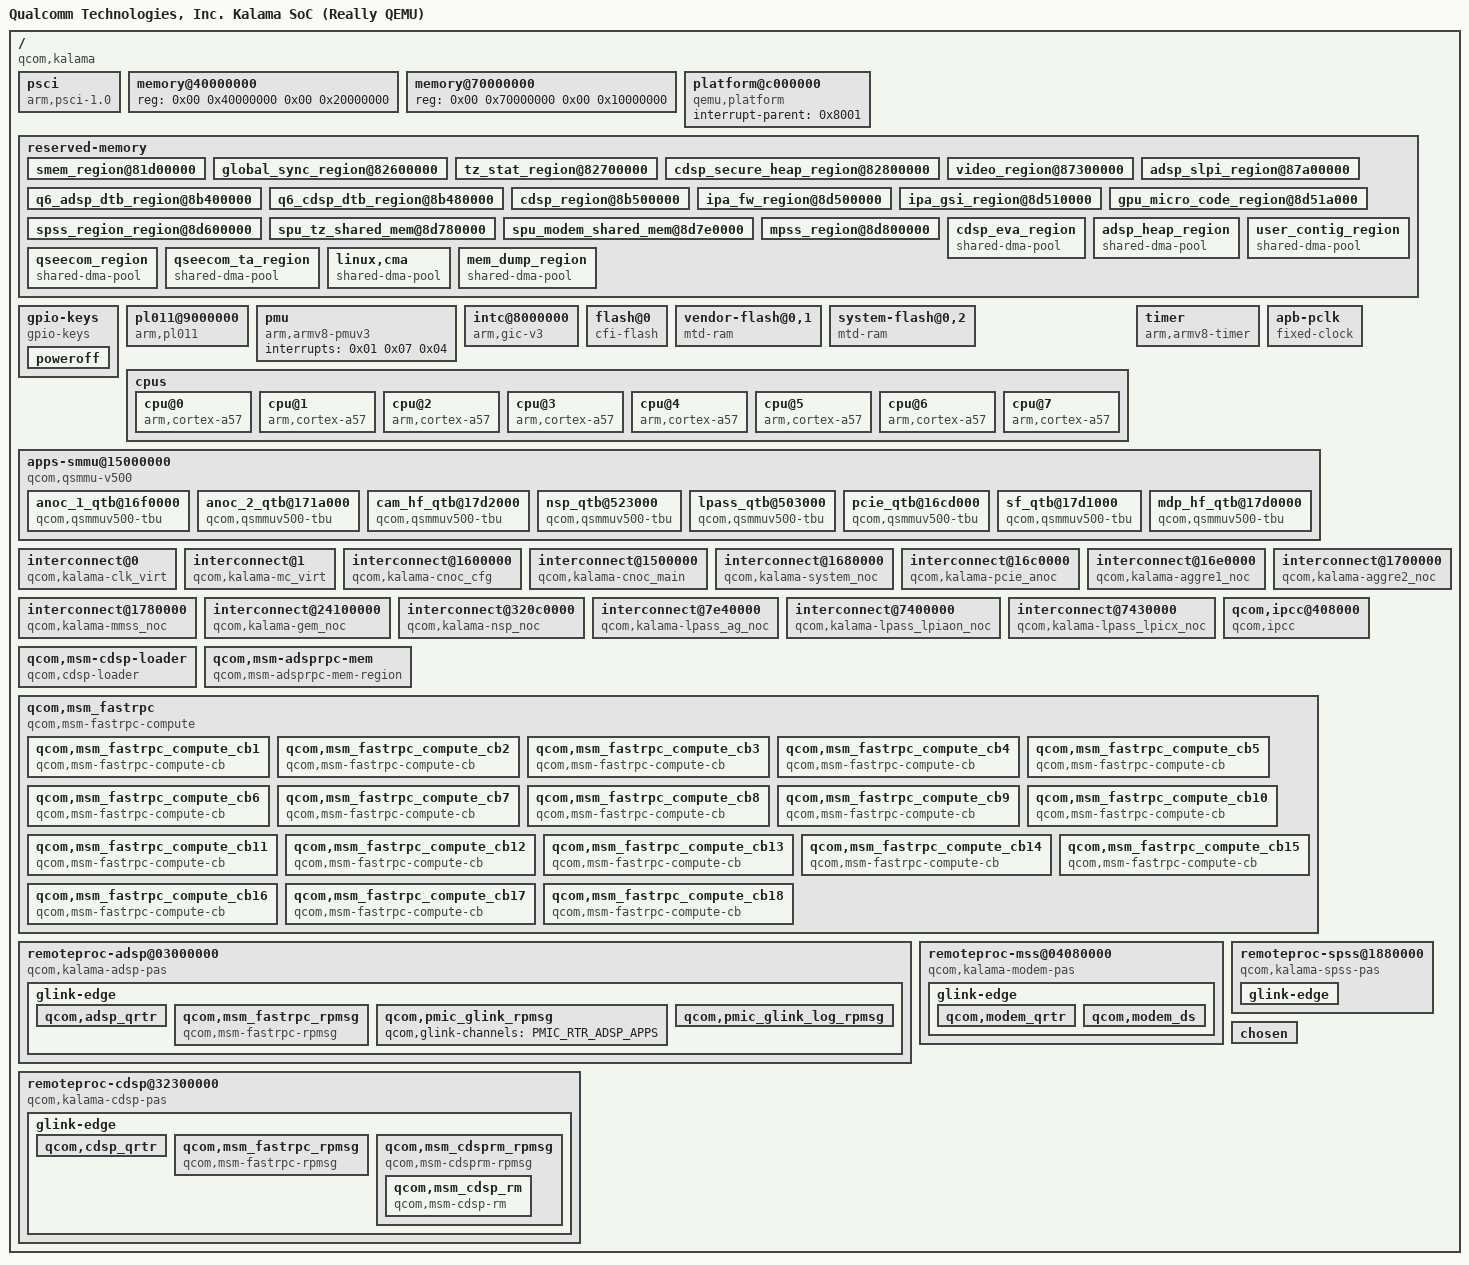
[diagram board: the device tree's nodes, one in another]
/dts-v1/;

/ {
	model = "Qualcomm Technologies, Inc. Kalama SoC (Really QEMU)";
	compatible = "qcom,kalama";
	qcom,msm-id = <0x207 0x10000>;
	interrupt-parent = <0x8001>;
	#size-cells = <0x02>;
	#address-cells = <0x02>;
	#compatible = "linux,dummy-virt";

	psci {
		migrate = <0xc4000005>;
		cpu_on = <0xc4000003>;
		cpu_off = <0x84000002>;
		cpu_suspend = <0xc4000001>;
		method = "smc";
		compatible = "arm,psci-1.0\0arm,psci";
	};

	memory@40000000 {
		reg = <0x00 0x40000000 0x00 0x20000000>;
		device_type = "memory";
	};

	memory@70000000 {
		reg = <0x00 0x70000000 0x00 0x10000000>;
		device_type = "memory";
	};

	platform@c000000 {
		interrupt-parent = <0x8001>;
		ranges = <0x00 0x00 0xc000000 0x2000000>;
		#address-cells = <0x01>;
		#size-cells = <0x01>;
		compatible = "qemu,platform\0simple-bus";
	};

	/*fw-cfg@9020000 {
		dma-coherent;
		reg = <0x00 0x9020000 0x00 0x18>;
		compatible = "qemu,fw-cfg-mmio";
	};
*/
	reserved-memory {
		#address-cells = <0x02>;
		#size-cells = <0x02>;
		ranges;
		phandle = <0x18d>;

		smem_region@81d00000 {
			no-map;
			reg = <0x00 0x81d00000 0x00 0x200000>;
			phandle = <0x50>;
		};

		global_sync_region@82600000 {
			no-map;
			reg = <0x00 0x82600000 0x00 0x100000>;
			phandle = <0x19b>;
		};

		tz_stat_region@82700000 {
			no-map;
			reg = <0x00 0x82700000 0x00 0x100000>;
			phandle = <0x19c>;
		};

		cdsp_secure_heap_region@82800000 {
			no-map;
			reg = <0x00 0x82800000 0x00 0x4600000>;
			phandle = <0x19d>;
		};

		video_region@87300000 {
			no-map;
			reg = <0x00 0x87300000 0x00 0x700000>;
			phandle = <0x19e>;
		};

		adsp_slpi_region@87a00000 {
			no-map;
			reg = <0x00 0x87a00000 0x00 0x3a00000>;
			phandle = <0x5e>;
		};

		q6_adsp_dtb_region@8b400000 {
			no-map;
			reg = <0x00 0x8b400000 0x00 0x80000>;
			phandle = <0x5f>;
		};

		q6_cdsp_dtb_region@8b480000 {
			no-map;
			reg = <0x00 0x8b480000 0x00 0x80000>;
			phandle = <0x64>;
		};

		cdsp_region@8b500000 {
			no-map;
			reg = <0x00 0x8b500000 0x00 0x2000000>;
			phandle = <0x63>;
		};

		ipa_fw_region@8d500000 {
			no-map;
			reg = <0x00 0x8d500000 0x00 0x10000>;
			phandle = <0x19f>;
		};

		ipa_gsi_region@8d510000 {
			no-map;
			reg = <0x00 0x8d510000 0x00 0xa000>;
			phandle = <0x1a0>;
		};

		gpu_micro_code_region@8d51a000 {
			no-map;
			reg = <0x00 0x8d51a000 0x00 0x2000>;
			phandle = <0x1a1>;
		};

		spss_region_region@8d600000 {
			no-map;
			reg = <0x00 0x8d600000 0x00 0x180000>;
			phandle = <0x6d>;
		};

		spu_tz_shared_mem@8d780000 {
			no-map;
			reg = <0x00 0x8d780000 0x00 0x60000>;
			phandle = <0x1a2>;
		};

		spu_modem_shared_mem@8d7e0000 {
			no-map;
			reg = <0x00 0x8d7e0000 0x00 0x20000>;
			phandle = <0x1a3>;
		};

		mpss_region@8d800000 {
			no-map;
			reg = <0x00 0x8d800000 0x00 0x13c00000>;
			phandle = <0x69>;
		};

		cdsp_eva_region {
			compatible = "shared-dma-pool";
			alloc-ranges = <0x00 0x00 0x00 0xffffffff>;
			reusable;
			alignment = <0x00 0x400000>;
			size = <0x00 0x400000>;
			phandle = <0x17d>;
		};

		adsp_heap_region {
			compatible = "shared-dma-pool";
			alloc-ranges = <0x00 0x00 0x00 0xffffffff>;
			reusable;
			alignment = <0x00 0x400000>;
			size = <0x00 0xc00000>;
			phandle = <0x58>;
		};

		user_contig_region {
			compatible = "shared-dma-pool";
			alloc-ranges = <0x00 0x00 0x00 0xffffffff>;
			reusable;
			alignment = <0x00 0x400000>;
			size = <0x00 0x1000000>;
			phandle = <0x31>;
		};

		qseecom_region {
			compatible = "shared-dma-pool";
			alloc-ranges = <0x00 0x00 0x00 0xffffffff>;
			reusable;
			alignment = <0x00 0x400000>;
			size = <0x00 0x1400000>;
			phandle = <0x2f>;
		};

		qseecom_ta_region {
			compatible = "shared-dma-pool";
			alloc-ranges = <0x00 0x00 0x00 0xffffffff>;
			reusable;
			alignment = <0x00 0x400000>;
			size = <0x00 0x1000000>;
			phandle = <0x30>;
		};

		linux,cma {
			compatible = "shared-dma-pool";
			alloc-ranges = <0x00 0x00 0x00 0xffffffff>;
			reusable;
			alignment = <0x00 0x400000>;
			size = <0x00 0x2000000>;
			linux,cma-default;
			phandle = <0x87>;
		};

		mem_dump_region {
			compatible = "shared-dma-pool";
			alloc-ranges = <0x01 0x00 0xfffffffe 0xffffffff>;
			reusable;
			alignment = <0x00 0x400000>;
			size = <0x00 0x3400000>;
			phandle = <0x173>;
		};
	};

	/*virtio_mmio@a000000 {
		dma-coherent;
		interrupts = <0x00 0x10 0x01>;
		reg = <0x00 0xa000000 0x00 0x200>;
		compatible = "virtio,mmio";
	};

	virtio_mmio@a000200 {
		dma-coherent;
		interrupts = <0x00 0x11 0x01>;
		reg = <0x00 0xa000200 0x00 0x200>;
		compatible = "virtio,mmio";
	};

	virtio_mmio@a000400 {
		dma-coherent;
		interrupts = <0x00 0x12 0x01>;
		reg = <0x00 0xa000400 0x00 0x200>;
		compatible = "virtio,mmio";
	};

	virtio_mmio@a000600 {
		dma-coherent;
		interrupts = <0x00 0x13 0x01>;
		reg = <0x00 0xa000600 0x00 0x200>;
		compatible = "virtio,mmio";
	};

	virtio_mmio@a000800 {
		dma-coherent;
		interrupts = <0x00 0x14 0x01>;
		reg = <0x00 0xa000800 0x00 0x200>;
		compatible = "virtio,mmio";
	};

	virtio_mmio@a000a00 {
		dma-coherent;
		interrupts = <0x00 0x15 0x01>;
		reg = <0x00 0xa000a00 0x00 0x200>;
		compatible = "virtio,mmio";
	};

	virtio_mmio@a000c00 {
		dma-coherent;
		interrupts = <0x00 0x16 0x01>;
		reg = <0x00 0xa000c00 0x00 0x200>;
		compatible = "virtio,mmio";
	};

	virtio_mmio@a000e00 {
		dma-coherent;
		interrupts = <0x00 0x17 0x01>;
		reg = <0x00 0xa000e00 0x00 0x200>;
		compatible = "virtio,mmio";
	};

	virtio_mmio@a001000 {
		dma-coherent;
		interrupts = <0x00 0x18 0x01>;
		reg = <0x00 0xa001000 0x00 0x200>;
		compatible = "virtio,mmio";
	};

	virtio_mmio@a001200 {
		dma-coherent;
		interrupts = <0x00 0x19 0x01>;
		reg = <0x00 0xa001200 0x00 0x200>;
		compatible = "virtio,mmio";
	};

	virtio_mmio@a001400 {
		dma-coherent;
		interrupts = <0x00 0x1a 0x01>;
		reg = <0x00 0xa001400 0x00 0x200>;
		compatible = "virtio,mmio";
	};

	virtio_mmio@a001600 {
		dma-coherent;
		interrupts = <0x00 0x1b 0x01>;
		reg = <0x00 0xa001600 0x00 0x200>;
		compatible = "virtio,mmio";
	};

	virtio_mmio@a001800 {
		dma-coherent;
		interrupts = <0x00 0x1c 0x01>;
		reg = <0x00 0xa001800 0x00 0x200>;
		compatible = "virtio,mmio";
	};

	virtio_mmio@a001a00 {
		dma-coherent;
		interrupts = <0x00 0x1d 0x01>;
		reg = <0x00 0xa001a00 0x00 0x200>;
		compatible = "virtio,mmio";
	};

	virtio_mmio@a001c00 {
		dma-coherent;
		interrupts = <0x00 0x1e 0x01>;
		reg = <0x00 0xa001c00 0x00 0x200>;
		compatible = "virtio,mmio";
	};

	virtio_mmio@a001e00 {
		dma-coherent;
		interrupts = <0x00 0x1f 0x01>;
		reg = <0x00 0xa001e00 0x00 0x200>;
		compatible = "virtio,mmio";
	};

	virtio_mmio@a002000 {
		dma-coherent;
		interrupts = <0x00 0x20 0x01>;
		reg = <0x00 0xa002000 0x00 0x200>;
		compatible = "virtio,mmio";
	};

	virtio_mmio@a002200 {
		dma-coherent;
		interrupts = <0x00 0x21 0x01>;
		reg = <0x00 0xa002200 0x00 0x200>;
		compatible = "virtio,mmio";
	};

	virtio_mmio@a002400 {
		dma-coherent;
		interrupts = <0x00 0x22 0x01>;
		reg = <0x00 0xa002400 0x00 0x200>;
		compatible = "virtio,mmio";
	};

	virtio_mmio@a002600 {
		dma-coherent;
		interrupts = <0x00 0x23 0x01>;
		reg = <0x00 0xa002600 0x00 0x200>;
		compatible = "virtio,mmio";
	};

	virtio_mmio@a002800 {
		dma-coherent;
		interrupts = <0x00 0x24 0x01>;
		reg = <0x00 0xa002800 0x00 0x200>;
		compatible = "virtio,mmio";
	};

	virtio_mmio@a002a00 {
		dma-coherent;
		interrupts = <0x00 0x25 0x01>;
		reg = <0x00 0xa002a00 0x00 0x200>;
		compatible = "virtio,mmio";
	};

	virtio_mmio@a002c00 {
		dma-coherent;
		interrupts = <0x00 0x26 0x01>;
		reg = <0x00 0xa002c00 0x00 0x200>;
		compatible = "virtio,mmio";
	};

	virtio_mmio@a002e00 {
		dma-coherent;
		interrupts = <0x00 0x27 0x01>;
		reg = <0x00 0xa002e00 0x00 0x200>;
		compatible = "virtio,mmio";
	};

	virtio_mmio@a003000 {
		dma-coherent;
		interrupts = <0x00 0x28 0x01>;
		reg = <0x00 0xa003000 0x00 0x200>;
		compatible = "virtio,mmio";
	};

	virtio_mmio@a003200 {
		dma-coherent;
		interrupts = <0x00 0x29 0x01>;
		reg = <0x00 0xa003200 0x00 0x200>;
		compatible = "virtio,mmio";
	};

	virtio_mmio@a003400 {
		dma-coherent;
		interrupts = <0x00 0x2a 0x01>;
		reg = <0x00 0xa003400 0x00 0x200>;
		compatible = "virtio,mmio";
	};

	virtio_mmio@a003600 {
		dma-coherent;
		interrupts = <0x00 0x2b 0x01>;
		reg = <0x00 0xa003600 0x00 0x200>;
		compatible = "virtio,mmio";
	};

	virtio_mmio@a003800 {
		dma-coherent;
		interrupts = <0x00 0x2c 0x01>;
		reg = <0x00 0xa003800 0x00 0x200>;
		compatible = "virtio,mmio";
	};

	virtio_mmio@a003a00 {
		dma-coherent;
		interrupts = <0x00 0x2d 0x01>;
		reg = <0x00 0xa003a00 0x00 0x200>;
		compatible = "virtio,mmio";
	};

	virtio_mmio@a003c00 {
		dma-coherent;
		interrupts = <0x00 0x2e 0x01>;
		reg = <0x00 0xa003c00 0x00 0x200>;
		compatible = "virtio,mmio";
	};

	virtio_mmio@a003e00 {
		dma-coherent;
		interrupts = <0x00 0x2f 0x01>;
		reg = <0x00 0xa003e00 0x00 0x200>;
		compatible = "virtio,mmio";
	};
*/
	gpio-keys {
		#address-cells = <0x01>;
		#size-cells = <0x00>;
		compatible = "gpio-keys";

		poweroff {
			gpios = <0x8002 0x03 0x00>;
			linux,code = <0x74>;
			label = "GPIO Key Poweroff";
		};
	};

	/*pl061@9030000 {
		phandle = <0x8002>;
		clock-names = "apb_pclk";
		clocks = <0x8000>;
		interrupts = <0x00 0x07 0x04>;
		gpio-controller;
		#gpio-cells = <0x02>;
		compatible = "arm,pl061\0arm,primecell";
		reg = <0x00 0x9030000 0x00 0x1000>;
	};*/

	/*pcie@10000000 {
		interrupt-map-mask = <0x1800 0x00 0x00 0x07>;
		interrupt-map = <0x00 0x00 0x00 0x01 0x8001 0x00 0x00 0x00 0x03 0x04 0x00 0x00 0x00 0x02 0x8001 0x00 0x00 0x00 0x04 0x04 0x00 0x00 0x00 0x03 0x8001 0x00 0x00 0x00 0x05 0x04 0x00 0x00 0x00 0x04 0x8001 0x00 0x00 0x00 0x06 0x04 0x800 0x00 0x00 0x01 0x8001 0x00 0x00 0x00 0x04 0x04 0x800 0x00 0x00 0x02 0x8001 0x00 0x00 0x00 0x05 0x04 0x800 0x00 0x00 0x03 0x8001 0x00 0x00 0x00 0x06 0x04 0x800 0x00 0x00 0x04 0x8001 0x00 0x00 0x00 0x03 0x04 0x1000 0x00 0x00 0x01 0x8001 0x00 0x00 0x00 0x05 0x04 0x1000 0x00 0x00 0x02 0x8001 0x00 0x00 0x00 0x06 0x04 0x1000 0x00 0x00 0x03 0x8001 0x00 0x00 0x00 0x03 0x04 0x1000 0x00 0x00 0x04 0x8001 0x00 0x00 0x00 0x04 0x04 0x1800 0x00 0x00 0x01 0x8001 0x00 0x00 0x00 0x06 0x04 0x1800 0x00 0x00 0x02 0x8001 0x00 0x00 0x00 0x03 0x04 0x1800 0x00 0x00 0x03 0x8001 0x00 0x00 0x00 0x04 0x04 0x1800 0x00 0x00 0x04 0x8001 0x00 0x00 0x00 0x05 0x04>;
		#interrupt-cells = <0x01>;
		ranges = <0x1000000 0x00 0x00 0x00 0x3eff0000 0x00 0x10000 0x2000000 0x00 0x10000000 0x00 0x10000000 0x00 0x2eff0000>;
		reg = <0x00 0x3f000000 0x00 0x1000000>;
		dma-coherent;
		bus-range = <0x00 0x0f>;
		linux,pci-domain = <0x00>;
		#size-cells = <0x02>;
		#address-cells = <0x03>;
		device_type = "pci";
		compatible = "pci-host-ecam-generic";
	};*/

	/*pl031@9010000 {
		clock-names = "apb_pclk";
		clocks = <0x8000>;
		interrupts = <0x00 0x02 0x04>;
		reg = <0x00 0x9010000 0x00 0x1000>;
		compatible = "arm,pl031\0arm,primecell";
	};*/

	pl011@9000000 {
		clock-names = "uartclk\0apb_pclk";
		clocks = <0x8000 0x8000>;
		interrupts = <0x00 0x01 0x04>;
		reg = <0x00 0x9000000 0x00 0x1000>;
		compatible = "arm,pl011\0arm,primecell";
	};

	pmu {
		interrupts = <0x01 0x07 0x04>;
		compatible = "arm,armv8-pmuv3";
	};

	intc@8000000 {
		phandle = <0x8001>;
		interrupts = <0x01 0x09 0x04>;
		reg = <0x00 0x8000000 0x00 0x10000 0x00 0x80a0000 0x00 0xf60000>;
		#redistributor-regions = <0x01>;
		compatible = "arm,gic-v3";
		ranges;
		#size-cells = <0x02>;
		#address-cells = <0x02>;
		interrupt-controller;
		#interrupt-cells = <0x03>;
	};

	flash@0 {
		bank-width = <0x04>;
		reg = <0x00 0x00 0x00 0x4000000 0x00 0x4000000 0x00 0x4000000>;
		compatible = "cfi-flash";
	};
	
	vendor-flash@0,1 {
		compatible = "mtd-ram";
		bank-width = <0x04>;
		reg = <0x00 0x10000000 0x00 0x20000000>;
	};
	system-flash@0,2 {
		compatible = "mtd-ram";
		bank-width = <0x04>;
		reg = <0x00 0x30000000 0x00 0x10000000>;
	};

	cpus {
		#size-cells = <0x00>;
		#address-cells = <0x01>;

		cpu@0 {
			reg = <0x00>;
			enable-method = "psci";
			compatible = "arm,cortex-a57";
			device_type = "cpu";
		};

		cpu@1 {
			reg = <0x01>;
			enable-method = "psci";
			compatible = "arm,cortex-a57";
			device_type = "cpu";
		};

		cpu@2 {
			reg = <0x02>;
			enable-method = "psci";
			compatible = "arm,cortex-a57";
			device_type = "cpu";
		};

		cpu@3 {
			reg = <0x03>;
			enable-method = "psci";
			compatible = "arm,cortex-a57";
			device_type = "cpu";
		};

		cpu@4 {
			reg = <0x04>;
			enable-method = "psci";
			compatible = "arm,cortex-a57";
			device_type = "cpu";
		};

		cpu@5 {
			reg = <0x05>;
			enable-method = "psci";
			compatible = "arm,cortex-a57";
			device_type = "cpu";
		};

		cpu@6 {
			reg = <0x06>;
			enable-method = "psci";
			compatible = "arm,cortex-a57";
			device_type = "cpu";
		};

		cpu@7 {
			reg = <0x07>;
			enable-method = "psci";
			compatible = "arm,cortex-a57";
			device_type = "cpu";
		};
	};

	timer {
		interrupts = <0x01 0x0d 0x04 0x01 0x0e 0x04 0x01 0x0b 0x04 0x01 0x0a 0x04>;
		always-on;
		compatible = "arm,armv8-timer\0arm,armv7-timer";
	};

	apb-pclk {
		phandle = <0x8000>;
		clock-output-names = "clk24mhz";
		clock-frequency = <0x16e3600>;
		#clock-cells = <0x00>;
		compatible = "fixed-clock";
	};

	apps-smmu@15000000 {
		compatible = "qcom,qsmmu-v500";
		reg = <0x15000000 0x100000>;
		#iommu-cells = <0x02>;
		qcom,use-3-lvl-tables;
		#global-interrupts = <0x01>;
		#size-cells = <0x01>;
		#address-cells = <0x01>;
		ranges;
		dma-coherent;
		interrupts = <0x00 0x41 0x04 0x00 0x61 0x04 0x00 0x62 0x04 0x00 0x63 0x04 0x00 0x64 0x04 0x00 0x65 0x04 0x00 0x66 0x04 0x00 0x67 0x04 0x00 0x68 0x04 0x00 0x69 0x04 0x00 0x6a 0x04 0x00 0x6b 0x04 0x00 0x6c 0x04 0x00 0x6d 0x04 0x00 0x6e 0x04 0x00 0x6f 0x04 0x00 0x70 0x04 0x00 0x71 0x04 0x00 0x72 0x04 0x00 0x73 0x04 0x00 0x74 0x04 0x00 0x75 0x04 0x00 0x76 0x04 0x00 0xb5 0x04 0x00 0xb6 0x04 0x00 0xb7 0x04 0x00 0xb8 0x04 0x00 0xb9 0x04 0x00 0xba 0x04 0x00 0xbb 0x04 0x00 0xbc 0x04 0x00 0xbd 0x04 0x00 0xbe 0x04 0x00 0xbf 0x04 0x00 0xc0 0x04 0x00 0x13b 0x04 0x00 0x13c 0x04 0x00 0x13d 0x04 0x00 0x13e 0x04 0x00 0x13f 0x04 0x00 0x140 0x04 0x00 0x141 0x04 0x00 0x142 0x04 0x00 0x143 0x04 0x00 0x144 0x04 0x00 0x145 0x04 0x00 0x146 0x04 0x00 0x147 0x04 0x00 0x148 0x04 0x00 0x149 0x04 0x00 0x14a 0x04 0x00 0x14b 0x04 0x00 0x14c 0x04 0x00 0x14d 0x04 0x00 0x14e 0x04 0x00 0x14f 0x04 0x00 0x150 0x04 0x00 0x151 0x04 0x00 0x152 0x04 0x00 0x153 0x04 0x00 0x154 0x04 0x00 0x155 0x04 0x00 0x156 0x04 0x00 0x157 0x04 0x00 0x158 0x04 0x00 0x159 0x04 0x00 0x18b 0x04 0x00 0x18c 0x04 0x00 0x18d 0x04 0x00 0x18e 0x04 0x00 0x18f 0x04 0x00 0x190 0x04 0x00 0x191 0x04 0x00 0x192 0x04 0x00 0x193 0x04 0x00 0x194 0x04 0x00 0x195 0x04 0x00 0x196 0x04 0x00 0x197 0x04 0x00 0x198 0x04 0x00 0x199 0x04 0x00 0x1a2 0x04 0x00 0x1a3 0x04 0x00 0x19c 0x04 0x00 0x1a5 0x04 0x00 0x2c2 0x04 0x00 0x1a7 0x04 0x00 0x1a8 0x04 0x00 0x1a9 0x04 0x00 0x2b1 0x04 0x00 0x2b2 0x04 0x00 0x2b3 0x04 0x00 0x2b4 0x04 0x00 0x2b5 0x04 0x00 0x2b6 0x04 0x00 0x2b7 0x04 0x00 0x2b8 0x04>;
		qcom,actlr = <0x18a0 0x40 0x103 0x800 0x20 0x01 0x1800 0xc0 0x01 0x1820 0x00 0x01 0x1860 0x00 0x01 0xc01 0x20 0x303 0xc02 0x20 0x303 0xc03 0x20 0x303 0xc04 0x20 0x303 0xc05 0x20 0x303 0xc06 0x20 0x303 0xc07 0x20 0x303 0xc08 0x20 0x303 0xc09 0x20 0x303 0xc0b 0x20 0x303 0xc0c 0x20 0x303 0xc0d 0x20 0x303 0xc0e 0x20 0x303 0xc0f 0x20 0x303 0x1961 0x00 0x303 0x1962 0x00 0x303 0x1963 0x00 0x303 0x1964 0x00 0x303 0x1965 0x00 0x303 0x1966 0x00 0x303 0x1967 0x00 0x303 0x1968 0x00 0x303 0x1969 0x00 0x303 0x196b 0x00 0x303 0x196c 0x00 0x303 0x196d 0x00 0x303 0x196e 0x00 0x303 0x196f 0x00 0x303 0x19c1 0x00 0x303 0x19c2 0x00 0x303 0x19c3 0x00 0x303 0x19c4 0x00 0x303 0x19c5 0x00 0x303 0x19c6 0x00 0x303 0x19c7 0x00 0x303 0x19c8 0x00 0x303 0x19c9 0x00 0x303 0x19cb 0x00 0x303 0x19cc 0x00 0x303 0x19cd 0x00 0x303 0x19ce 0x00 0x303 0x19cf 0x00 0x303 0x1c00 0x02 0x01 0x1c01 0x00 0x01 0x1920 0x00 0x103 0x1923 0x00 0x103 0x1924 0x00 0x103 0x1940 0x00 0x103 0x1941 0x04 0x103 0x1943 0x00 0x103 0x1944 0x00 0x103 0x1947 0x00 0x103>;
		phandle = <0x4c>;

		anoc_1_qtb@16f0000 {
			compatible = "qcom,qsmmuv500-tbu\0qcom,qtb500";
			reg = <0x16f0000 0x1000>;
			qcom,stream-id-range = <0x00 0x400>;
			qcom,iova-width = <0x24>;
			interconnects = <0x84 0x09 0x5c 0x200>;
			qcom,num-qtb-ports = <0x01>;
			phandle = <0x232>;
		};

		anoc_2_qtb@171a000 {
			compatible = "qcom,qsmmuv500-tbu\0qcom,qtb500";
			reg = <0x171a000 0x1000>;
			qcom,stream-id-range = <0x400 0x400>;
			qcom,iova-width = <0x24>;
			interconnects = <0x84 0x0a 0x5c 0x200>;
			qcom,num-qtb-ports = <0x01>;
			phandle = <0x233>;
		};

		cam_hf_qtb@17d2000 {
			compatible = "qcom,qsmmuv500-tbu\0qcom,qtb500";
			reg = <0x17d2000 0x1000>;
			qcom,stream-id-range = <0x800 0x400>;
			qcom,iova-width = <0x24>;
			interconnects = <0x85 0x0b 0x5c 0x200>;
			qcom,num-qtb-ports = <0x02>;
			phandle = <0x234>;
		};

		nsp_qtb@523000 {
			compatible = "qcom,qsmmuv500-tbu\0qcom,qtb500";
			reg = <0x523000 0x1000>;
			qcom,stream-id-range = <0xc00 0x400>;
			qcom,iova-width = <0x22>;
			interconnects = <0x65 0x2a 0x5c 0x200>;
			qcom,num-qtb-ports = <0x02>;
			phandle = <0x235>;
		};

		lpass_qtb@503000 {
			compatible = "qcom,qsmmuv500-tbu\0qcom,qtb500";
			reg = <0x503000 0x1000>;
			qcom,stream-id-range = <0x1000 0x400>;
			qcom,iova-width = <0x20>;
			interconnects = <0x5b 0x29 0x5c 0x200>;
			qcom,num-qtb-ports = <0x01>;
			phandle = <0x236>;
		};

		pcie_qtb@16cd000 {
			compatible = "qcom,qsmmuv500-tbu\0qcom,qtb500";
			reg = <0x16cd000 0x1000>;
			qcom,stream-id-range = <0x1400 0x400>;
			qcom,iova-width = <0x24>;
			interconnects = <0x86 0x2d 0x5c 0x200>;
			qcom,num-qtb-ports = <0x01>;
			phandle = <0x237>;
		};

		sf_qtb@17d1000 {
			compatible = "qcom,qsmmuv500-tbu\0qcom,qtb500";
			reg = <0x17d1000 0x1000>;
			qcom,stream-id-range = <0x1800 0x400>;
			qcom,iova-width = <0x24>;
			interconnects = <0x85 0x1d 0x5c 0x200>;
			qcom,num-qtb-ports = <0x02>;
			phandle = <0x238>;
		};

		mdp_hf_qtb@17d0000 {
			compatible = "qcom,qsmmuv500-tbu\0qcom,qtb500";
			reg = <0x17d0000 0x1000>;
			qcom,stream-id-range = <0x1c00 0x400>;
			qcom,iova-width = <0x20>;
			interconnects = <0x85 0x14 0x5c 0x200>;
			qcom,num-qtb-ports = <0x02>;
			phandle = <0x239>;
		};
	};

	interconnect@0 {
		compatible = "qcom,kalama-clk_virt";
		#interconnect-cells = <0x01>;
		qcom,bcm-voter-names = "hlos";
		qcom,bcm-voters = <0x2b>;
		phandle = <0x1c9>;
	};

	interconnect@1 {
		compatible = "qcom,kalama-mc_virt";
		#interconnect-cells = <0x01>;
		qcom,bcm-voter-names = "hlos\0disp";
		qcom,bcm-voters = <0x2b 0x2c>;
		phandle = <0x5c>;
	};

	interconnect@1600000 {
		compatible = "qcom,kalama-cnoc_cfg";
		reg = <0x1600000 0x6200>;
		#interconnect-cells = <0x01>;
		qcom,bcm-voter-names = "hlos";
		qcom,bcm-voters = <0x2b>;
		phandle = <0x177>;
	};

	interconnect@1500000 {
		compatible = "qcom,kalama-cnoc_main";
		reg = <0x1500000 0x13080>;
		#interconnect-cells = <0x01>;
		qcom,bcm-voter-names = "hlos";
		qcom,bcm-voters = <0x2b>;
		phandle = <0x1ca>;
	};

	interconnect@1680000 {
		compatible = "qcom,kalama-system_noc";
		reg = <0x1680000 0x1d080>;
		#interconnect-cells = <0x01>;
		qcom,bcm-voter-names = "hlos";
		qcom,bcm-voters = <0x2b>;
		phandle = <0x84>;
	};

	interconnect@16c0000 {
		compatible = "qcom,kalama-pcie_anoc";
		reg = <0x16c0000 0x12200>;
		#interconnect-cells = <0x01>;
		clocks = <0x2d 0x00 0x2d 0x0a>;
		qcom,bcm-voter-names = "hlos";
		qcom,bcm-voters = <0x2b>;
		qcom,skip-qos;
		phandle = <0x86>;
	};

	interconnect@16e0000 {
		compatible = "qcom,kalama-aggre1_noc";
		reg = <0x16e0000 0x14400>;
		#interconnect-cells = <0x01>;
		clocks = <0x2d 0x01 0x2d 0x03>;
		qcom,bcm-voter-names = "hlos";
		qcom,bcm-voters = <0x2b>;
		qcom,skip-qos;
		phandle = <0x176>;
	};

	interconnect@1700000 {
		compatible = "qcom,kalama-aggre2_noc";
		reg = <0x1700000 0x1e400>;
		#interconnect-cells = <0x01>;
		qcom,bcm-voter-names = "hlos";
		qcom,bcm-voters = <0x2b>;
		clocks = <0x2e 0x0c>;
		qcom,skip-qos;
		phandle = <0x5d>;
	};

	interconnect@1780000 {
		compatible = "qcom,kalama-mmss_noc";
		reg = <0x1780000 0x5b800>;
		#interconnect-cells = <0x01>;
		qcom,bcm-voter-names = "hlos\0disp";
		qcom,bcm-voters = <0x2b 0x2c>;
		qcom,skip-qos;
		phandle = <0x85>;
	};

	interconnect@24100000 {
		compatible = "qcom,kalama-gem_noc";
		reg = <0x24100000 0xbb800>;
		#interconnect-cells = <0x01>;
		qcom,bcm-voter-names = "hlos\0disp";
		qcom,bcm-voters = <0x2b 0x2c>;
		qcom,skip-qos;
		phandle = <0x76>;
	};

	interconnect@320c0000 {
		compatible = "qcom,kalama-nsp_noc";
		reg = <0x320c0000 0xe080>;
		#interconnect-cells = <0x01>;
		qcom,bcm-voter-names = "hlos";
		qcom,bcm-voters = <0x2b>;
		phandle = <0x65>;
	};

	interconnect@7e40000 {
		compatible = "qcom,kalama-lpass_ag_noc";
		reg = <0x7e40000 0xe080>;
		#interconnect-cells = <0x01>;
		qcom,bcm-voter-names = "hlos";
		qcom,bcm-voters = <0x2b>;
		phandle = <0x1cb>;
	};

	interconnect@7400000 {
		compatible = "qcom,kalama-lpass_lpiaon_noc";
		reg = <0x7400000 0x19080>;
		#interconnect-cells = <0x01>;
		qcom,bcm-voter-names = "hlos";
		qcom,bcm-voters = <0x2b>;
		phandle = <0x1cc>;
	};

	interconnect@7430000 {
		compatible = "qcom,kalama-lpass_lpicx_noc";
		reg = <0x7430000 0x3a200>;
		#interconnect-cells = <0x01>;
		qcom,bcm-voter-names = "hlos";
		qcom,bcm-voters = <0x2b>;
		phandle = <0x5b>;
	};

	qcom,ipcc@408000 {
		compatible = "qcom,ipcc";
		reg = <0x408000 0x1000>;
		interrupts = <0x00 0xe5 0x04>;
		interrupt-controller;
		#interrupt-cells = <0x03>;
		#mbox-cells = <0x02>;
		phandle = <0x52>;
	};

	qcom,msm-cdsp-loader {
		compatible = "qcom,cdsp-loader";
		qcom,proc-img-to-load = "cdsp";
		qcom,rproc-handle = <0x57>;
	};

	qcom,msm-adsprpc-mem {
		compatible = "qcom,msm-adsprpc-mem-region";
		memory-region = <0x58>;
		restrict-access;
	};

	qcom,msm_fastrpc {
		compatible = "qcom,msm-fastrpc-compute";
		qcom,adsp-remoteheap-vmid = <0x16 0x25>;
		qcom,fastrpc-adsp-audio-pdr;
		qcom,fastrpc-adsp-sensors-pdr;
		qcom,rpc-latency-us = <0xeb>;
		qcom,fastrpc-gids = <0xb5c>;
		qcom,qos-cores = <0x00 0x01 0x02 0x03>;
		phandle = <0x21b>;

		qcom,msm_fastrpc_compute_cb1 {
			compatible = "qcom,msm-fastrpc-compute-cb";
			label = "cdsprpc-smd";
			iommus = <0x4c 0x1961 0x00 0x4c 0xc01 0x20 0x4c 0x19c1 0x10>;
			qcom,iommu-dma-addr-pool = <0x80000000 0x78000000>;
			qcom,iommu-faults = "stall-disable\0HUPCF";
			dma-coherent;
		};

		qcom,msm_fastrpc_compute_cb2 {
			compatible = "qcom,msm-fastrpc-compute-cb";
			label = "cdsprpc-smd";
			iommus = <0x4c 0x1962 0x00 0x4c 0xc02 0x20 0x4c 0x19c2 0x10>;
			qcom,iommu-dma-addr-pool = <0x80000000 0x78000000>;
			qcom,iommu-faults = "stall-disable\0HUPCF";
			dma-coherent;
		};

		qcom,msm_fastrpc_compute_cb3 {
			compatible = "qcom,msm-fastrpc-compute-cb";
			label = "cdsprpc-smd";
			iommus = <0x4c 0x1963 0x00 0x4c 0xc03 0x20 0x4c 0x19c3 0x10>;
			qcom,iommu-dma-addr-pool = <0x80000000 0x78000000>;
			qcom,iommu-faults = "stall-disable\0HUPCF";
			dma-coherent;
		};

		qcom,msm_fastrpc_compute_cb4 {
			compatible = "qcom,msm-fastrpc-compute-cb";
			label = "cdsprpc-smd";
			iommus = <0x4c 0x1964 0x00 0x4c 0xc04 0x20 0x4c 0x19c4 0x10>;
			qcom,iommu-dma-addr-pool = <0x80000000 0x78000000>;
			qcom,iommu-faults = "stall-disable\0HUPCF";
			dma-coherent;
		};

		qcom,msm_fastrpc_compute_cb5 {
			compatible = "qcom,msm-fastrpc-compute-cb";
			label = "cdsprpc-smd";
			iommus = <0x4c 0x1965 0x00 0x4c 0xc05 0x20 0x4c 0x19c5 0x10>;
			qcom,iommu-dma-addr-pool = <0x80000000 0x78000000>;
			qcom,iommu-faults = "stall-disable\0HUPCF";
			dma-coherent;
		};

		qcom,msm_fastrpc_compute_cb6 {
			compatible = "qcom,msm-fastrpc-compute-cb";
			label = "cdsprpc-smd";
			iommus = <0x4c 0x1966 0x00 0x4c 0xc06 0x20 0x4c 0x19c6 0x10>;
			qcom,iommu-dma-addr-pool = <0x80000000 0x78000000>;
			qcom,iommu-faults = "stall-disable\0HUPCF";
			dma-coherent;
		};

		qcom,msm_fastrpc_compute_cb7 {
			compatible = "qcom,msm-fastrpc-compute-cb";
			label = "cdsprpc-smd";
			iommus = <0x4c 0x1967 0x00 0x4c 0xc07 0x20 0x4c 0x19c7 0x10>;
			qcom,iommu-dma-addr-pool = <0x80000000 0x78000000>;
			qcom,iommu-faults = "stall-disable\0HUPCF";
			dma-coherent;
		};

		qcom,msm_fastrpc_compute_cb8 {
			compatible = "qcom,msm-fastrpc-compute-cb";
			label = "cdsprpc-smd";
			iommus = <0x4c 0x1968 0x00 0x4c 0xc08 0x20 0x4c 0x19c8 0x10>;
			qcom,iommu-dma-addr-pool = <0x80000000 0x78000000>;
			qcom,iommu-faults = "stall-disable\0HUPCF";
			dma-coherent;
		};

		qcom,msm_fastrpc_compute_cb9 {
			compatible = "qcom,msm-fastrpc-compute-cb";
			label = "cdsprpc-smd";
			qcom,secure-context-bank;
			iommus = <0x4c 0x1969 0x00 0x4c 0xc09 0x20 0x4c 0x19c9 0x10>;
			qcom,iommu-dma-addr-pool = <0x60000000 0x78000000>;
			qcom,iommu-faults = "stall-disable\0HUPCF";
			qcom,iommu-vmid = <0x0a>;
			dma-coherent;
		};

		qcom,msm_fastrpc_compute_cb10 {
			compatible = "qcom,msm-fastrpc-compute-cb";
			label = "adsprpc-smd";
			iommus = <0x4c 0x1003 0x80 0x4c 0x1063 0x00>;
			qcom,iommu-dma-addr-pool = <0x80000000 0x78000000>;
			qcom,iommu-faults = "stall-disable\0HUPCF";
			dma-coherent;
		};

		qcom,msm_fastrpc_compute_cb11 {
			compatible = "qcom,msm-fastrpc-compute-cb";
			label = "adsprpc-smd";
			iommus = <0x4c 0x1004 0x80 0x4c 0x1064 0x00>;
			qcom,iommu-dma-addr-pool = <0x80000000 0x78000000>;
			qcom,iommu-faults = "stall-disable\0HUPCF";
			dma-coherent;
		};

		qcom,msm_fastrpc_compute_cb12 {
			compatible = "qcom,msm-fastrpc-compute-cb";
			label = "adsprpc-smd";
			iommus = <0x4c 0x1005 0x80 0x4c 0x1065 0x00>;
			qcom,iommu-dma-addr-pool = <0x80000000 0x78000000>;
			qcom,iommu-faults = "stall-disable\0HUPCF";
			dma-coherent;
		};

		qcom,msm_fastrpc_compute_cb13 {
			compatible = "qcom,msm-fastrpc-compute-cb";
			label = "adsprpc-smd";
			iommus = <0x4c 0x1006 0x80 0x4c 0x1066 0x00>;
			qcom,iommu-dma-addr-pool = <0x80000000 0x78000000>;
			qcom,iommu-faults = "stall-disable\0HUPCF";
			dma-coherent;
		};

		qcom,msm_fastrpc_compute_cb14 {
			compatible = "qcom,msm-fastrpc-compute-cb";
			label = "adsprpc-smd";
			iommus = <0x4c 0x1007 0x80 0x4c 0x1067 0x00>;
			qcom,iommu-dma-addr-pool = <0x80000000 0x78000000>;
			qcom,iommu-faults = "stall-disable\0HUPCF";
			dma-coherent;
		};

		qcom,msm_fastrpc_compute_cb15 {
			compatible = "qcom,msm-fastrpc-compute-cb";
			label = "cdsprpc-smd";
			iommus = <0x4c 0x196c 0x00 0x4c 0xc0c 0x20 0x4c 0x19cc 0x10>;
			qcom,iommu-dma-addr-pool = <0x80000000 0x78000000>;
			qcom,iommu-faults = "stall-disable\0HUPCF";
			dma-coherent;
		};

		qcom,msm_fastrpc_compute_cb16 {
			compatible = "qcom,msm-fastrpc-compute-cb";
			label = "cdsprpc-smd";
			iommus = <0x4c 0x196d 0x00 0x4c 0xc0d 0x20 0x4c 0x19cd 0x10>;
			qcom,iommu-dma-addr-pool = <0x80000000 0x78000000>;
			qcom,iommu-faults = "stall-disable\0HUPCF";
			dma-coherent;
		};

		qcom,msm_fastrpc_compute_cb17 {
			compatible = "qcom,msm-fastrpc-compute-cb";
			label = "cdsprpc-smd";
			iommus = <0x4c 0x196e 0x00 0x4c 0xc0e 0x20 0x4c 0x19ce 0x10>;
			qcom,iommu-dma-addr-pool = <0x80000000 0x78000000>;
			qcom,iommu-faults = "stall-disable\0HUPCF";
			dma-coherent;
		};

		qcom,msm_fastrpc_compute_cb18 {
			compatible = "qcom,msm-fastrpc-compute-cb";
			label = "cdsprpc-smd";
			iommus = <0x4c 0x196f 0x00 0x4c 0xc0f 0x20 0x4c 0x19cf 0x10>;
			qcom,iommu-dma-addr-pool = <0x80000000 0x78000000>;
			qcom,iommu-faults = "stall-disable\0HUPCF";
			dma-coherent;
		};
	};

	remoteproc-adsp@03000000 {
		compatible = "qcom,kalama-adsp-pas";
		reg = <0x3000000 0x10000>;
		status = "ok";
		cx-supply = <0x59>;
		cx-uV-uA = <0x180 0x00>;
		mx-supply = <0x5a>;
		mx-uV-uA = <0x180 0x00>;
		reg-names = "cx\0mx";
		clocks = <0x2e 0x00>;
		clock-names = "xo";
		qcom,qmp = <0x53>;
		interconnects = <0x5b 0x29 0x5c 0x200 0x5d 0x27 0x5c 0x200>;
		interconnect-names = "rproc_ddr\0crypto_ddr";
		memory-region = <0x5e 0x5f>;
		interrupts-extended = <0x32 0x06 0x01 0x60 0x00 0x00 0x60 0x02 0x00 0x60 0x01 0x00 0x60 0x03 0x00>;
		interrupt-names = "wdog\0fatal\0handover\0ready\0stop-ack";
		qcom,smem-states = <0x61 0x00>;
		qcom,smem-state-names = "stop";
		phandle = <0x21c>;

		glink-edge {
			qcom,remote-pid = <0x02>;
			transport = "smem";
			mboxes = <0x52 0x03 0x00>;
			mbox-names = "adsp_smem";
			interrupt-parent = <0x52>;
			interrupts = <0x03 0x00 0x01>;
			label = "adsp";
			qcom,glink-label = "lpass";
			phandle = <0x21d>;

			qcom,adsp_qrtr {
				qcom,glink-channels = "IPCRTR";
				qcom,intents = <0x800 0x05 0x2000 0x03 0x4400 0x02>;
			};

			qcom,msm_fastrpc_rpmsg {
				compatible = "qcom,msm-fastrpc-rpmsg";
				qcom,glink-channels = "fastrpcglink-apps-dsp";
				qcom,intents = <0x64 0x40>;
			};

			qcom,pmic_glink_rpmsg {
				qcom,glink-channels = "PMIC_RTR_ADSP_APPS";
			};

			qcom,pmic_glink_log_rpmsg {
				qcom,glink-channels = "PMIC_LOGS_ADSP_APPS";
				qcom,intents = <0x800 0x05 0xc00 0x03 0x2000 0x01>;
			};
		};
	};

	remoteproc-cdsp@32300000 {
		compatible = "qcom,kalama-cdsp-pas";
		reg = <0x32300000 0x10000>;
		status = "ok";
		cx-supply = <0x21>;
		cx-uV-uA = <0x180 0x186a0>;
		mx-supply = <0x25>;
		mx-uV-uA = <0x180 0x186a0>;
		nsp-supply = <0x62>;
		nsp-uV-uA = <0x180 0x186a0>;
		reg-names = "cx\0mx\0nsp";
		memory-region = <0x63 0x64>;
		clocks = <0x2e 0x00>;
		clock-names = "xo";
		qcom,qmp = <0x53>;
		interconnects = <0x65 0x2a 0x5c 0x200 0x5d 0x27 0x5c 0x200>;
		interconnect-names = "rproc_ddr\0crypto_ddr";
		interrupts-extended = <0x01 0x00 0x242 0x01 0x66 0x00 0x00 0x66 0x02 0x00 0x66 0x01 0x00 0x66 0x03 0x00>;
		interrupt-names = "wdog\0fatal\0handover\0ready\0stop-ack";
		qcom,smem-states = <0x67 0x00>;
		qcom,smem-state-names = "stop";
		phandle = <0x57>;

		glink-edge {
			qcom,remote-pid = <0x05>;
			transport = "smem";
			mboxes = <0x52 0x06 0x00>;
			mbox-names = "cdsp_smem";
			interrupt-parent = <0x52>;
			interrupts = <0x06 0x00 0x01>;
			label = "cdsp";
			qcom,glink-label = "cdsp";

			qcom,cdsp_qrtr {
				qcom,glink-channels = "IPCRTR";
				qcom,intents = <0x800 0x05 0x2000 0x03 0x4400 0x02>;
			};

			qcom,msm_fastrpc_rpmsg {
				compatible = "qcom,msm-fastrpc-rpmsg";
				qcom,glink-channels = "fastrpcglink-apps-dsp";
				qcom,intents = <0x64 0x40>;
			};

			qcom,msm_cdsprm_rpmsg {
				compatible = "qcom,msm-cdsprm-rpmsg";
				qcom,glink-channels = "cdsprmglink-apps-dsp";
				qcom,intents = <0x20 0x0c>;

				qcom,msm_cdsp_rm {
					compatible = "qcom,msm-cdsp-rm";
					qcom,qos-latency-us = <0x46>;
					qcom,qos-maxhold-ms = <0x14>;
					phandle = <0x21e>;
				};
			};
		};
	};

	remoteproc-mss@04080000 {
		compatible = "qcom,kalama-modem-pas";
		reg = <0x4080000 0x10000>;
		status = "ok";
		clocks = <0x2e 0x00>;
		clock-names = "xo";
		cx-supply = <0x21>;
		cx-uV-uA = <0x180 0x186a0>;
		mx-supply = <0x68>;
		mx-uV-uA = <0x180 0x186a0>;
		reg-names = "cx\0mx";
		qcom,qmp = <0x53>;
		interconnects = <0x5d 0x27 0x5c 0x200>;
		interconnect-names = "crypto_ddr";
		memory-region = <0x69 0x6a>;
		interrupts-extended = <0x01 0x00 0x108 0x01 0x6b 0x00 0x00 0x6b 0x02 0x00 0x6b 0x01 0x00 0x6b 0x03 0x00 0x6b 0x07 0x00>;
		interrupt-names = "wdog\0fatal\0handover\0ready\0stop-ack\0shutdown-ack";
		qcom,smem-states = <0x6c 0x00>;
		qcom,smem-state-names = "stop";
		phandle = <0x21f>;

		glink-edge {
			qcom,remote-pid = <0x01>;
			transport = "smem";
			mboxes = <0x52 0x02 0x00>;
			mbox-names = "mpss_smem";
			interrupt-parent = <0x52>;
			interrupts = <0x02 0x00 0x01>;
			label = "modem";
			qcom,glink-label = "mpss";

			qcom,modem_qrtr {
				qcom,glink-channels = "IPCRTR";
				qcom,low-latency;
				qcom,intents = <0x800 0x05 0x2000 0x03 0x4400 0x02>;
			};

			qcom,modem_ds {
				qcom,glink-channels = "DS";
				qcom,intents = <0x4000 0x02>;
			};
		};
	};

	remoteproc-spss@1880000 {
		compatible = "qcom,kalama-spss-pas";
		ranges;
		reg = <0x188101c 0x04 0x1881024 0x04 0x1881028 0x04 0x188103c 0x04 0x1881100 0x04 0x1882014 0x04>;
		reg-names = "sp2soc_irq_status\0sp2soc_irq_clr\0sp2soc_irq_mask\0rmb_err\0rmb_general_purpose\0rmb_err_spare2";
		interrupts = <0x00 0x160 0x01>;
		cx-supply = <0x21>;
		cx-uV-uA = <0x180 0x186a0>;
		clocks = <0x2e 0x00>;
		clock-names = "xo";
		qcom,proxy-clock-names = "xo";
		status = "ok";
		memory-region = <0x6d>;
		qcom,spss-scsr-bits = <0x18 0x19>;
		qcom,extra-size = <0x1000>;
		interconnects = <0x5d 0x27 0x5c 0x200>;
		interconnect-names = "crypto_ddr";
		phandle = <0x220>;

		glink-edge {
			qcom,remote-pid = <0x08>;
			mboxes = <0x52 0x10 0x00>;
			mbox-names = "spss_spss";
			interrupt-parent = <0x52>;
			interrupts = <0x10 0x00 0x01>;
			reg = <0x1885008 0x08 0x1885010 0x04>;
			reg-names = "qcom,spss-addr\0qcom,spss-size";
			label = "spss";
			qcom,glink-label = "spss";
		};
	};

	chosen {
		bootargs = "rw root=/dev/ram rdinit=/sbin/init earlyprintk=serial,ttyAMA0 console=ttyAMA0 -netdev user,id=eth0 -device virtio-net-device,netdev=eth0 -drive file=rootfs.ext4,if=none,format=raw,id=hd0 -device virtio-blk-device,drive=hd0";
		linux,initrd-start = "D@\0";
		linux,initrd-end = <0x466cea00>;
		stdout-path = "/pl011@9000000";
		kaslr-seed = <0xdec2698b 0x996c3b6b>;
	};

	__symbols__ {
		usb_emu_phy = "/soc/phy@a784000";
		usb_nop_phy = "/soc/usb_nop_phy";
		pmr735d_l_trip2 = "/soc/thermal-zones/pmr735d_l_tz/trips/trip2";
		pmr735d_l_trip1 = "/soc/thermal-zones/pmr735d_l_tz/trips/trip1";
		pmr735d_l_trip0 = "/soc/thermal-zones/pmr735d_l_tz/trips/trip0";
		pmr735d_l_temp_alarm = "/soc/thermal-zones/pmr735d_l_tz";
		pmr735d_k_trip2 = "/soc/thermal-zones/pmr735d_k_tz/trips/trip2";
		pmr735d_k_trip1 = "/soc/thermal-zones/pmr735d_k_tz/trips/trip1";
		pmr735d_k_trip0 = "/soc/thermal-zones/pmr735d_k_tz/trips/trip0";
		pmr735d_k_temp_alarm = "/soc/thermal-zones/pmr735d_k_tz";
		pmr735d_l_gpios = "/soc/qcom,spmi@c42d000/qcom,pmr735d@b/pinctrl@8800";
		pmr735d_l_tz = "/soc/qcom,spmi@c42d000/qcom,pmr735d@b/qcom,temp-alarm@a00";
		pmr735d_k_gpios = "/soc/qcom,spmi@c42d000/qcom,pmr735d@a/pinctrl@8800";
		pmr735d_k_tz = "/soc/qcom,spmi@c42d000/qcom,pmr735d@a/qcom,temp-alarm@a00";
		pmk8550_rtc = "/soc/qcom,spmi@c42d000/qcom,pmk8550@0/rtc@6100";
		pmk8550_gpios = "/soc/qcom,spmi@c42d000/qcom,pmk8550@0/pinctrl@b800";
		pmk8550_sdam_22 = "/soc/qcom,spmi@c42d000/qcom,pmk8550@0/sdam@8500";
		pmk8550_sdam_21 = "/soc/qcom,spmi@c42d000/qcom,pmk8550@0/sdam@8400";
		pmk8550_sdam_5 = "/soc/qcom,spmi@c42d000/qcom,pmk8550@0/sdam@7400";
		pmk8550_sdam_2 = "/soc/qcom,spmi@c42d000/qcom,pmk8550@0/sdam@7100";
		pm8550vs_g_trip2 = "/soc/thermal-zones/pm8550vs_g_tz/trips/trip2";
		pm8550vs_g_trip1 = "/soc/thermal-zones/pm8550vs_g_tz/trips/trip1";
		pm8550vs_g_trip0 = "/soc/thermal-zones/pm8550vs_g_tz/trips/trip0";
		pm8550vs_g_temp_alarm = "/soc/thermal-zones/pm8550vs_g_tz";
		pm8550vs_e_trip2 = "/soc/thermal-zones/pm8550vs_e_tz/trips/trip2";
		pm8550vs_e_trip1 = "/soc/thermal-zones/pm8550vs_e_tz/trips/trip1";
		pm8550vs_e_trip0 = "/soc/thermal-zones/pm8550vs_e_tz/trips/trip0";
		pm8550vs_e_temp_alarm = "/soc/thermal-zones/pm8550vs_e_tz";
		pm8550vs_d_trip2 = "/soc/thermal-zones/pm8550vs_d_tz/trips/trip2";
		pm8550vs_d_trip1 = "/soc/thermal-zones/pm8550vs_d_tz/trips/trip1";
		pm8550vs_d_trip0 = "/soc/thermal-zones/pm8550vs_d_tz/trips/trip0";
		pm8550vs_d_temp_alarm = "/soc/thermal-zones/pm8550vs_d_tz";
		pm8550vs_c_trip2 = "/soc/thermal-zones/pm8550vs_c_tz/trips/trip2";
		pm8550vs_c_trip1 = "/soc/thermal-zones/pm8550vs_c_tz/trips/trip1";
		pm8550vs_c_trip0 = "/soc/thermal-zones/pm8550vs_c_tz/trips/trip0";
		pm8550vs_c_temp_alarm = "/soc/thermal-zones/pm8550vs_c_tz";
		pm8550vs_g_gpios = "/soc/qcom,spmi@c42d000/qcom,pm8550vs@6/pinctrl@8800";
		pm8550vs_g_tz = "/soc/qcom,spmi@c42d000/qcom,pm8550vs@6/qcom,temp-alarm@a00";
		pm8550vs_g = "/soc/qcom,spmi@c42d000/qcom,pm8550vs@6";
		pm8550vs_e_gpios = "/soc/qcom,spmi@c42d000/qcom,pm8550vs@4/pinctrl@8800";
		pm8550vs_e_tz = "/soc/qcom,spmi@c42d000/qcom,pm8550vs@4/qcom,temp-alarm@a00";
		pm8550vs_e = "/soc/qcom,spmi@c42d000/qcom,pm8550vs@4";
		pm8550vs_d_gpios = "/soc/qcom,spmi@c42d000/qcom,pm8550vs@3/pinctrl@8800";
		pm8550vs_d_tz = "/soc/qcom,spmi@c42d000/qcom,pm8550vs@3/qcom,temp-alarm@a00";
		pm8550vs_d = "/soc/qcom,spmi@c42d000/qcom,pm8550vs@3";
		pm8550vs_c_gpios = "/soc/qcom,spmi@c42d000/qcom,pm8550vs@2/pinctrl@8800";
		pm8550vs_c_tz = "/soc/qcom,spmi@c42d000/qcom,pm8550vs@2/qcom,temp-alarm@a00";
		pm8550vs_c = "/soc/qcom,spmi@c42d000/qcom,pm8550vs@2";
		pm8550ve_f_trip2 = "/soc/thermal-zones/pm8550ve_f__tz/trips/trip2";
		pm8550ve_f_trip1 = "/soc/thermal-zones/pm8550ve_f__tz/trips/trip1";
		pm8550ve_f_trip0 = "/soc/thermal-zones/pm8550ve_f__tz/trips/trip0";
		pm8550ve_f_temp_alarm = "/soc/thermal-zones/pm8550ve_f__tz";
		pm8550ve_f_gpios = "/soc/qcom,spmi@c42d000/qcom,pm8550ve_f@5/pinctrl@8800";
		pm8550ve_f_tz = "/soc/qcom,spmi@c42d000/qcom,pm8550ve_f@5/qcom,temp-alarm@a00";
		pm8550b_trip2 = "/soc/thermal-zones/pm8550b_tz/trips/trip2";
		pm8550b_trip1 = "/soc/thermal-zones/pm8550b_tz/trips/trip1";
		pm8550b_trip0 = "/soc/thermal-zones/pm8550b_tz/trips/trip0";
		pm8550b_temp_alarm = "/soc/thermal-zones/pm8550b_tz";
		pm8550b_gpios = "/soc/qcom,spmi@c42d000/qcom,pm8550b@7/pinctrl@8800";
		pm8550b_tz = "/soc/qcom,spmi@c42d000/qcom,pm8550b@7/qcom,temp-alarm@a00";
		pm8550_trip2 = "/soc/thermal-zones/pm8550_tz/trips/trip2";
		pm8550_trip1 = "/soc/thermal-zones/pm8550_tz/trips/trip1";
		pm8550_trip0 = "/soc/thermal-zones/pm8550_tz/trips/trip0";
		pm8550_temp_alarm = "/soc/thermal-zones/pm8550_tz";
		pm8550_rgb = "/soc/qcom,spmi@c42d000/qcom,pm8550@1/qcom,leds@ef00";
		pm8550_pwm_2 = "/soc/qcom,spmi@c42d000/qcom,pm8550@1/pwms@eb00";
		pm8550_pwm_1 = "/soc/qcom,spmi@c42d000/qcom,pm8550@1/pwms@e800";
		key_vol_up_default = "/soc/qcom,spmi@c42d000/qcom,pm8550@1/pinctrl@8800/key_vol_up/key_vol_up_default";
		pm8550_gpios = "/soc/qcom,spmi@c42d000/qcom,pm8550@1/pinctrl@8800";
		pm8550_tz = "/soc/qcom,spmi@c42d000/qcom,pm8550@1/qcom,temp-alarm@a00";
		chosen = "/chosen";
		reserved_memory = "/reserved-memory";
		hyp_qheebsp_mem = "/reserved-memory/hyp_qheebsp_region@80000000";
		hyp_data_mem = "/reserved-memory/hyp_data_region@80200000";
		hyp_rm_hypx_mem = "/reserved-memory/hyp_rm_hypx_region@80600000";
		cpusys_vm_mem = "/reserved-memory/cpusys_vm_region@80800000";
		hyp_heap_mem = "/reserved-memory/hyp_heap_region@80c00000";
		hyp_tags_mem = "/reserved-memory/hyp_tags_region@80e00000";
		xbl_dt_log_mem = "/reserved-memory/xbl_dt_log@81a00000";
		xbl_ramdump_mem = "/reserved-memory/xbl_ramdump_region@81a40000";
		aop_image_mem = "/reserved-memory/aop_image_region@81c00000";
		aop_cmd_db_mem = "/reserved-memory/aop_cmd_db_region@81c60000";
		aop_config_mem = "/reserved-memory/aop_config_region@81c80000";
		tme_crash_dump_mem = "/reserved-memory/tme_crash_dump_region@81ca0000";
		tme_log_mem = "/reserved-memory/tme_log_region@81ce0000";
		uefi_log_mem = "/reserved-memory/uefi_log_region@81ce4000";
		smem_mem = "/reserved-memory/smem_region@81d00000";
		global_sync_mem = "/reserved-memory/global_sync_region@82600000";
		tz_stat_mem = "/reserved-memory/tz_stat_region@82700000";
		cdsp_secure_heap = "/reserved-memory/cdsp_secure_heap_region@82800000";
		video_mem = "/reserved-memory/video_region@87300000";
		adsp_slpi_mem = "/reserved-memory/adsp_slpi_region@87a00000";
		q6_adsp_dtb_mem = "/reserved-memory/q6_adsp_dtb_region@8b400000";
		q6_cdsp_dtb_mem = "/reserved-memory/q6_cdsp_dtb_region@8b480000";
		cdsp_mem = "/reserved-memory/cdsp_region@8b500000";
		ipa_fw_mem = "/reserved-memory/ipa_fw_region@8d500000";
		ipa_gsi_mem = "/reserved-memory/ipa_gsi_region@8d510000";
		gpu_micro_code_mem = "/reserved-memory/gpu_micro_code_region@8d51a000";
		spss_region_mem = "/reserved-memory/spss_region_region@8d600000";
		spu_tz_shared_mem = "/reserved-memory/spu_tz_shared_mem@8d780000";
		spu_modem_shared_mem = "/reserved-memory/spu_modem_shared_mem@8d7e0000";
		mpss_mem = "/reserved-memory/mpss_region@8d800000";
		q6_mpss_dtb_mem = "/reserved-memory/q6_mpss_dtb_region@a1400000";
		cvp_mem = "/reserved-memory/cvp_region@a1500000";
		camera_mem = "/reserved-memory/camera_region@a1c00000";
		cpucp_fw_mem = "/reserved-memory/cpucp_fw_region@d8000000";
		xbl_sc_mem = "/reserved-memory/xbl_sc_region@d8100000";
		tz_reserved_mem = "/reserved-memory/tz_reserved_region@d8140000";
		qtee_mem = "/reserved-memory/qtee_region@d8300000";
		trusted_apps_mem = "/reserved-memory/trusted_apps_region@d8800000";
		tz_tags_mem = "/reserved-memory/tz_tags_region@e1200000";
		trust_ui_vm_mem = "/reserved-memory/trust_ui_vm_region@f3e00000";
		trust_ui_vm_qrtr = "/reserved-memory/trust_ui_vm_qrtr@f80f3000";
		trust_ui_vm_vblk0_ring = "/reserved-memory/trust_ui_vm_vblk0_ring@f80fc000";
		trust_ui_vm_swiotlb = "/reserved-memory/trust_ui_vm_swiotlb@f8100000";
		oem_vm_mem = "/reserved-memory/oem_vm_region@f8200000";
		hyp_ext_tags_mem = "/reserved-memory/hyp_ext_tags_region@fd200000";
		llcc_lpi_mem = "/reserved-memory/llcc_lpi_region@ffa00000";
		cdsp_eva_mem = "/reserved-memory/cdsp_eva_region";
		adsp_mem_heap = "/reserved-memory/adsp_heap_region";
		user_contig_mem = "/reserved-memory/user_contig_region";
		qseecom_mem = "/reserved-memory/qseecom_region";
		qseecom_ta_mem = "/reserved-memory/qseecom_ta_region";
		system_cma = "/reserved-memory/linux,cma";
		dump_mem = "/reserved-memory/mem_dump_region";
		aliases = "/aliases";
		sram = "/sram@17D09400";
		cpu_scp_lpri = "/sram@17D09400/scmi-shmem@0";
		firmware = "/firmware";
		qcom_tzlog = "/firmware/tz-log@146AA720";
		CPU0 = "/cpus/cpu@0";
		L2_0 = "/cpus/cpu@0/l2-cache";
		L3_0 = "/cpus/cpu@0/l2-cache/l3-cache";
		CPU1 = "/cpus/cpu@100";
		L2_1 = "/cpus/cpu@100/l2-cache";
		CPU2 = "/cpus/cpu@200";
		CPU3 = "/cpus/cpu@300";
		L2_3 = "/cpus/cpu@300/l2-cache";
		CPU4 = "/cpus/cpu@400";
		L2_4 = "/cpus/cpu@400/l2-cache";
		CPU5 = "/cpus/cpu@500";
		L2_5 = "/cpus/cpu@500/l2-cache";
		CPU6 = "/cpus/cpu@600";
		L2_6 = "/cpus/cpu@600/l2-cache";
		CPU7 = "/cpus/cpu@700";
		L2_7 = "/cpus/cpu@700/l2-cache";
		SILVER_OFF = "/idle-states/silver-c4";
		GOLD_OFF = "/idle-states/gold-c4";
		CLUSTER_PWR_DN = "/idle-states/cluster-d4";
		APSS_OFF = "/idle-states/cluster-e3";
		soc = "/soc";
		CPU_PD0 = "/soc/psci/cpu-pd0";
		CPU_PD1 = "/soc/psci/cpu-pd1";
		CPU_PD2 = "/soc/psci/cpu-pd2";
		CPU_PD3 = "/soc/psci/cpu-pd3";
		CPU_PD4 = "/soc/psci/cpu-pd4";
		CPU_PD5 = "/soc/psci/cpu-pd5";
		CPU_PD6 = "/soc/psci/cpu-pd6";
		CPU_PD7 = "/soc/psci/cpu-pd7";
		CLUSTER_PD = "/soc/psci/cluster-pd";
		slimbam = "/soc/bamdma@6C04000";
		slim_msm = "/soc/slim@6C40000";
		intc = "/soc/interrupt-controller@17100000";
		gic_its = "/soc/interrupt-controller@17100000/msi-controller@17140000";
		apps_rsc = "/soc/rsc@17a00000";
		apps_rsc_drv2 = "/soc/rsc@17a00000/drv@2";
		apps_bcm_voter = "/soc/rsc@17a00000/drv@2/bcm_voter";
		rpmhcc = "/soc/rsc@17a00000/drv@2/clock-controller";
		dcvs_fp = "/soc/rsc@17a00000/drv@2/qcom,dcvs-fp";
		VDD_LPI_CX_LEVEL = "/soc/rsc@17a00000/drv@2/rpmh-regulator-lcxlvl/regulator-pm-v6d-s4-level";
		S4D_LEVEL = "/soc/rsc@17a00000/drv@2/rpmh-regulator-lcxlvl/regulator-pm-v6d-s4-level";
		pm_v6d_s4_level = "/soc/rsc@17a00000/drv@2/rpmh-regulator-lcxlvl/regulator-pm-v6d-s4-level";
		VDD_GFX_LEVEL = "/soc/rsc@17a00000/drv@2/rpmh-regulator-gfxlvl/regulator-pm-v6d-s5-level";
		S5D_LEVEL = "/soc/rsc@17a00000/drv@2/rpmh-regulator-gfxlvl/regulator-pm-v6d-s5-level";
		pm_v6d_s5_level = "/soc/rsc@17a00000/drv@2/rpmh-regulator-gfxlvl/regulator-pm-v6d-s5-level";
		VDD_LPI_MX_LEVEL = "/soc/rsc@17a00000/drv@2/rpmh-regulator-lmxlvl/regulator-pm-v6d-l2-level";
		L2D_LEVEL = "/soc/rsc@17a00000/drv@2/rpmh-regulator-lmxlvl/regulator-pm-v6d-l2-level";
		pm_v6d_l2_level = "/soc/rsc@17a00000/drv@2/rpmh-regulator-lmxlvl/regulator-pm-v6d-l2-level";
		VDD_CX_LEVEL = "/soc/rsc@17a00000/drv@2/rpmh-regulator-cxlvl/regulator-pm-v6e-s6-level";
		S6E_LEVEL = "/soc/rsc@17a00000/drv@2/rpmh-regulator-cxlvl/regulator-pm-v6e-s6-level";
		pm_v6e_s6_level = "/soc/rsc@17a00000/drv@2/rpmh-regulator-cxlvl/regulator-pm-v6e-s6-level";
		VDD_CX_LEVEL_AO = "/soc/rsc@17a00000/drv@2/rpmh-regulator-cxlvl/regulator-pm-v6e-s6-level-ao";
		S6E_LEVEL_AO = "/soc/rsc@17a00000/drv@2/rpmh-regulator-cxlvl/regulator-pm-v6e-s6-level-ao";
		pm_v6e_s6_level_ao = "/soc/rsc@17a00000/drv@2/rpmh-regulator-cxlvl/regulator-pm-v6e-s6-level-ao";
		VDD_CX_MMCX_SUPPLY_LEVEL = "/soc/rsc@17a00000/drv@2/rpmh-regulator-cxlvl/regulator-pm-v6e-s6-mmcx-sup-level";
		VDD_MMCX_LEVEL = "/soc/rsc@17a00000/drv@2/rpmh-regulator-mmcxlvl/regulator-pm-v6e-s1-level";
		VDD_MM_LEVEL = "/soc/rsc@17a00000/drv@2/rpmh-regulator-mmcxlvl/regulator-pm-v6e-s1-level";
		S1E_LEVEL = "/soc/rsc@17a00000/drv@2/rpmh-regulator-mmcxlvl/regulator-pm-v6e-s1-level";
		pm_v6e_s1_level = "/soc/rsc@17a00000/drv@2/rpmh-regulator-mmcxlvl/regulator-pm-v6e-s1-level";
		VDD_MMCX_LEVEL_AO = "/soc/rsc@17a00000/drv@2/rpmh-regulator-mmcxlvl/regulator-pm-v6e-s1-level-ao";
		VDD_MM_LEVEL_AO = "/soc/rsc@17a00000/drv@2/rpmh-regulator-mmcxlvl/regulator-pm-v6e-s1-level-ao";
		S1E_LEVEL_AO = "/soc/rsc@17a00000/drv@2/rpmh-regulator-mmcxlvl/regulator-pm-v6e-s1-level-ao";
		pm_v6e_s1_level_ao = "/soc/rsc@17a00000/drv@2/rpmh-regulator-mmcxlvl/regulator-pm-v6e-s1-level-ao";
		VDD_MXA_LEVEL = "/soc/rsc@17a00000/drv@2/rpmh-regulator-mxlvl/regulator-pm-v6e-s3-level";
		S3E_LEVEL = "/soc/rsc@17a00000/drv@2/rpmh-regulator-mxlvl/regulator-pm-v6e-s3-level";
		pm_v6e_s3_level = "/soc/rsc@17a00000/drv@2/rpmh-regulator-mxlvl/regulator-pm-v6e-s3-level";
		VDD_MXA_LEVEL_AO = "/soc/rsc@17a00000/drv@2/rpmh-regulator-mxlvl/regulator-pm-v6e-s3-level-ao";
		S3E_LEVEL_AO = "/soc/rsc@17a00000/drv@2/rpmh-regulator-mxlvl/regulator-pm-v6e-s3-level-ao";
		pm_v6e_s3_level_ao = "/soc/rsc@17a00000/drv@2/rpmh-regulator-mxlvl/regulator-pm-v6e-s3-level-ao";
		VDD_NSP_LEVEL = "/soc/rsc@17a00000/drv@2/rpmh-regulator-nsplvl/regulator-pm-v8-s1-level";
		S1F_LEVEL = "/soc/rsc@17a00000/drv@2/rpmh-regulator-nsplvl/regulator-pm-v8-s1-level";
		pm_v8_s1_level = "/soc/rsc@17a00000/drv@2/rpmh-regulator-nsplvl/regulator-pm-v8-s1-level";
		VDD_EBI_LEVEL = "/soc/rsc@17a00000/drv@2/rpmh-regulator-ebilvl/regulator-pm-v8-s3-level";
		S3F_LEVEL = "/soc/rsc@17a00000/drv@2/rpmh-regulator-ebilvl/regulator-pm-v8-s3-level";
		pm_v8_s3_level = "/soc/rsc@17a00000/drv@2/rpmh-regulator-ebilvl/regulator-pm-v8-s3-level";
		VDD_MXC_LEVEL = "/soc/rsc@17a00000/drv@2/rpmh-regulator-mxclvl/regulator-pm-v8-s5-level";
		S5F_LEVEL = "/soc/rsc@17a00000/drv@2/rpmh-regulator-mxclvl/regulator-pm-v8-s5-level";
		pm_v8_s5_level = "/soc/rsc@17a00000/drv@2/rpmh-regulator-mxclvl/regulator-pm-v8-s5-level";
		VDD_MXC_LEVEL_AO = "/soc/rsc@17a00000/drv@2/rpmh-regulator-mxclvl/regulator-pm-v8-s5-level-ao";
		S5F_LEVEL_AO = "/soc/rsc@17a00000/drv@2/rpmh-regulator-mxclvl/regulator-pm-v8-s5-level-ao";
		pm_v8_s5_level_ao = "/soc/rsc@17a00000/drv@2/rpmh-regulator-mxclvl/regulator-pm-v8-s5-level-ao";
		VDD_MXC_MMCX_VOTER_LEVEL = "/soc/rsc@17a00000/drv@2/rpmh-regulator-mxclvl/regulator-pm-v8-s5-mmcx-voter-level";
		VDD_MXC_MM_VOTER_LEVEL = "/soc/rsc@17a00000/drv@2/rpmh-regulator-mxclvl/regulator-pm-v8-s5-mmcx-voter-level";
		VDD_MM_MXC_VOTER_LEVEL = "/soc/rsc@17a00000/drv@2/rpmh-regulator-mxclvl/regulator-pm-v8-s5-mmcx-voter-level";
		VDD_MXC_GFX_VOTER_LEVEL = "/soc/rsc@17a00000/drv@2/rpmh-regulator-mxclvl/regulator-pm-v8-s5-gfx-voter-level";
		VDD_GFX_MXC_VOTER_LEVEL = "/soc/rsc@17a00000/drv@2/rpmh-regulator-mxclvl/regulator-pm-v8-s5-gfx-voter-level";
		VDD_MODEM_LEVEL = "/soc/rsc@17a00000/drv@2/rpmh-regulator-msslvl/regulator-pm-v8-s7-level";
		S7F_LEVEL = "/soc/rsc@17a00000/drv@2/rpmh-regulator-msslvl/regulator-pm-v8-s7-level";
		pm_v8_s7_level = "/soc/rsc@17a00000/drv@2/rpmh-regulator-msslvl/regulator-pm-v8-s7-level";
		arch_timer = "/soc/timer";
		cam_rsc = "/soc/rsc@add9000";
		cam_rsc_drv0 = "/soc/rsc@add9000/drv@0";
		cam_rsc_drv1 = "/soc/rsc@add9000/drv@1";
		cam_rsc_drv2 = "/soc/rsc@add9000/drv@2";
		disp_rsc = "/soc/rsc@af20000";
		disp_rsc_drv0 = "/soc/rsc@af20000/drv@0";
		disp_bcm_voter = "/soc/rsc@af20000/drv@0/bcm_voter";
		memtimer = "/soc/timer@17420000";
		rimps = "/soc/qcom,rimps@17400000";
		scmi = "/soc/qcom,scmi";
		scmi_pmu = "/soc/qcom,scmi/protocol@86";
		scmi_c1dcvs = "/soc/qcom,scmi/protocol@87";
		rimps_log = "/soc/qcom,rimps_log@17d09c00";
		cpu_pmu = "/soc/cpu-pmu";
		clk_virt = "/soc/interconnect@0";
		mc_virt = "/soc/interconnect@1";
		config_noc = "/soc/interconnect@1600000";
		cnoc_main = "/soc/interconnect@1500000";
		system_noc = "/soc/interconnect@1680000";
		pcie_noc = "/soc/interconnect@16c0000";
		aggre1_noc = "/soc/interconnect@16e0000";
		aggre2_noc = "/soc/interconnect@1700000";
		mmss_noc = "/soc/interconnect@1780000";
		gem_noc = "/soc/interconnect@24100000";
		nsp_noc = "/soc/interconnect@320c0000";
		lpass_ag_noc = "/soc/interconnect@7e40000";
		lpass_lpiaon_noc = "/soc/interconnect@7400000";
		lpass_lpicx_noc = "/soc/interconnect@7430000";
		pdc = "/soc/interrupt-controller@b220000";
		vendor_hooks = "/soc/qcom,cpu-vendor-hooks";
		qcom_qseecom = "/soc/qseecom@c1700000";
		tlmm = "/soc/pinctrl@f000000";
		qupv3_se7_2uart_pins = "/soc/pinctrl@f000000/qupv3_se7_2uart_pins";
		qupv3_se7_2uart_active = "/soc/pinctrl@f000000/qupv3_se7_2uart_pins/qupv3_se7_2uart_active";
		qupv3_se7_2uart_sleep = "/soc/pinctrl@f000000/qupv3_se7_2uart_pins/qupv3_se7_2uart_sleep";
		sdc2_on = "/soc/pinctrl@f000000/sdc2_on";
		sdc2_off = "/soc/pinctrl@f000000/sdc2_off";
		aux0_pcm_clk_sleep = "/soc/pinctrl@f000000/aux0_pcm_clk/aux0_pcm_clk_sleep";
		aux0_pcm_clk_active = "/soc/pinctrl@f000000/aux0_pcm_clk/aux0_pcm_clk_active";
		aux0_pcm_ws_sleep = "/soc/pinctrl@f000000/aux0_pcm_ws/aux0_pcm_ws_sleep";
		aux0_pcm_ws_active = "/soc/pinctrl@f000000/aux0_pcm_ws/aux0_pcm_ws_active";
		aux0_pcm_din_sleep = "/soc/pinctrl@f000000/aux0_pcm_din/aux0_pcm_din_sleep";
		aux0_pcm_din_active = "/soc/pinctrl@f000000/aux0_pcm_din/aux0_pcm_din_active";
		aux0_pcm_dout_sleep = "/soc/pinctrl@f000000/aux0_pcm_dout/aux0_pcm_dout_sleep";
		aux0_pcm_dout_active = "/soc/pinctrl@f000000/aux0_pcm_dout/aux0_pcm_dout_active";
		aux1_pcm_clk_sleep = "/soc/pinctrl@f000000/aux1_pcm_clk/aux1_pcm_clk_sleep";
		aux1_pcm_clk_active = "/soc/pinctrl@f000000/aux1_pcm_clk/aux1_pcm_clk_active";
		aux1_pcm_ws_sleep = "/soc/pinctrl@f000000/aux1_pcm_ws/aux1_pcm_ws_sleep";
		aux1_pcm_ws_active = "/soc/pinctrl@f000000/aux1_pcm_ws/aux1_pcm_ws_active";
		aux1_pcm_din_sleep = "/soc/pinctrl@f000000/aux1_pcm_din/aux1_pcm_din_sleep";
		aux1_pcm_din_active = "/soc/pinctrl@f000000/aux1_pcm_din/aux1_pcm_din_active";
		aux1_pcm_dout_sleep = "/soc/pinctrl@f000000/aux1_pcm_dout/aux1_pcm_dout_sleep";
		aux1_pcm_dout_active = "/soc/pinctrl@f000000/aux1_pcm_dout/aux1_pcm_dout_active";
		tdm0_clk_sleep = "/soc/pinctrl@f000000/tdm0_clk/tdm0_clk_sleep";
		tdm0_clk_active = "/soc/pinctrl@f000000/tdm0_clk/tdm0_clk_active";
		tdm0_ws_sleep = "/soc/pinctrl@f000000/tdm0_ws/tdm0_ws_sleep";
		tdm0_ws_active = "/soc/pinctrl@f000000/tdm0_ws/tdm0_ws_active";
		tdm0_din_sleep = "/soc/pinctrl@f000000/tdm0_din/tdm0_din_sleep";
		tdm0_din_active = "/soc/pinctrl@f000000/tdm0_din/tdm0_din_active";
		tdm0_dout_sleep = "/soc/pinctrl@f000000/tdm0_dout/tdm0_dout_sleep";
		tdm0_dout_active = "/soc/pinctrl@f000000/tdm0_dout/tdm0_dout_active";
		tdm1_clk_sleep = "/soc/pinctrl@f000000/tdm1_clk/tdm1_clk_sleep";
		tdm1_clk_active = "/soc/pinctrl@f000000/tdm1_clk/tdm1_clk_active";
		tdm1_ws_sleep = "/soc/pinctrl@f000000/tdm1_ws/tdm1_ws_sleep";
		tdm1_ws_active = "/soc/pinctrl@f000000/tdm1_ws/tdm1_ws_active";
		tdm1_din_sleep = "/soc/pinctrl@f000000/tdm1_din/tdm1_din_sleep";
		tdm1_din_active = "/soc/pinctrl@f000000/tdm1_din/tdm1_din_active";
		tdm1_dout_sleep = "/soc/pinctrl@f000000/tdm1_dout/tdm1_dout_sleep";
		tdm1_dout_active = "/soc/pinctrl@f000000/tdm1_dout/tdm1_dout_active";
		i2s0_sck_sleep = "/soc/pinctrl@f000000/i2s0_sck/i2s0_sck_sleep";
		i2s0_sck_active = "/soc/pinctrl@f000000/i2s0_sck/i2s0_sck_active";
		i2s0_ws_sleep = "/soc/pinctrl@f000000/i2s0_ws/i2s0_ws_sleep";
		i2s0_ws_active = "/soc/pinctrl@f000000/i2s0_ws/i2s0_ws_active";
		i2s0_sd0_sleep = "/soc/pinctrl@f000000/i2s0_sd0/i2s0_sd0_sleep";
		i2s0_sd0_active = "/soc/pinctrl@f000000/i2s0_sd0/i2s0_sd0_active";
		i2s0_sd1_sleep = "/soc/pinctrl@f000000/i2s0_sd1/i2s0_sd1_sleep";
		i2s0_sd1_active = "/soc/pinctrl@f000000/i2s0_sd1/i2s0_sd1_active";
		i2s1_sck_sleep = "/soc/pinctrl@f000000/i2s1_sck/i2s1_sck_sleep";
		i2s1_sck_active = "/soc/pinctrl@f000000/i2s1_sck/i2s1_sck_active";
		i2s1_ws_sleep = "/soc/pinctrl@f000000/i2s1_ws/i2s1_ws_sleep";
		i2s1_ws_active = "/soc/pinctrl@f000000/i2s1_ws/i2s1_ws_active";
		i2s1_sd0_sleep = "/soc/pinctrl@f000000/i2s1_sd0/i2s1_sd0_sleep";
		i2s1_sd0_active = "/soc/pinctrl@f000000/i2s1_sd0/i2s1_sd0_active";
		i2s1_sd1_sleep = "/soc/pinctrl@f000000/i2s1_sd1/i2s1_sd1_sleep";
		i2s1_sd1_active = "/soc/pinctrl@f000000/i2s1_sd1/i2s1_sd1_active";
		wcd938x_reset_active = "/soc/pinctrl@f000000/wcd938x_reset_active";
		wcd938x_reset_sleep = "/soc/pinctrl@f000000/wcd938x_reset_sleep";
		pcie0_perst_default = "/soc/pinctrl@f000000/pcie0/pcie0_perst_default";
		pcie0_clkreq_default = "/soc/pinctrl@f000000/pcie0/pcie0_clkreq_default";
		pcie0_wake_default = "/soc/pinctrl@f000000/pcie0/pcie0_wake_default";
		pcie0_clkreq_sleep = "/soc/pinctrl@f000000/pcie0/pcie0_clkreq_sleep";
		xo_board = "/soc/clocks/xo_board";
		sleep_clk = "/soc/clocks/sleep_clk";
		camcc = "/soc/clock-controller@ade0000";
		dispcc = "/soc/clock-controller@af00000";
		pcie_0_pipe_clk = "/soc/pcie_0_pipe_clk";
		pcie_1_phy_aux_clk = "/soc/pcie_1_phy_aux_clk";
		pcie_1_pipe_clk = "/soc/pcie_1_pipe_clk";
		ufs_phy_rx_symbol_0_clk = "/soc/ufs_phy_rx_symbol_0_clk";
		ufs_phy_rx_symbol_1_clk = "/soc/ufs_phy_rx_symbol_1_clk";
		ufs_phy_tx_symbol_0_clk = "/soc/ufs_phy_tx_symbol_0_clk";
		usb3_phy_wrapper_gcc_usb30_pipe_clk = "/soc/usb3_phy_wrapper_gcc_usb30_pipe_clk";
		gcc = "/soc/clock-controller@100000";
		gpucc = "/soc/clock-controller@3d90000";
		tcsrcc = "/soc/clock-controller@1fc0000";
		videocc = "/soc/clock-controller@abf0000";
		apsscc = "/soc/syscon@17A80000";
		mccc = "/soc/syscon@240ba000";
		debugcc = "/soc/qcom,cc-debug";
		cam_cc_bps_gdsc = "/soc/qcom,gdsc@adf0004";
		cam_cc_ife_0_gdsc = "/soc/qcom,gdsc@adf1004";
		cam_cc_ife_1_gdsc = "/soc/qcom,gdsc@adf2004";
		cam_cc_ife_2_gdsc = "/soc/qcom,gdsc@adf2294";
		cam_cc_ipe_0_gdsc = "/soc/qcom,gdsc@adf03b8";
		cam_cc_sbi_gdsc = "/soc/qcom,gdsc@adf052c";
		cam_cc_sfe_0_gdsc = "/soc/qcom,gdsc@adf3280";
		cam_cc_sfe_1_gdsc = "/soc/qcom,gdsc@adf33e0";
		cam_cc_titan_top_gdsc = "/soc/qcom,gdsc@adf4058";
		disp_cc_mdss_core_gdsc = "/soc/qcom,gdsc@af09000";
		disp_cc_mdss_core_int2_gdsc = "/soc/qcom,gdsc@af0b000";
		gcc_apcs_gdsc_vote_ctrl = "/soc/syscon@152020";
		gcc_pcie_0_gdsc = "/soc/qcom,gdsc@16b004";
		gcc_pcie_0_phy_gdsc = "/soc/qcom,gdsc@16c000";
		gcc_pcie_1_gdsc = "/soc/qcom,gdsc@18d004";
		gcc_pcie_1_phy_gdsc = "/soc/qcom,gdsc@18e000";
		gcc_ufs_mem_phy_gdsc = "/soc/qcom,gdsc@19e000";
		gcc_ufs_phy_gdsc = "/soc/qcom,gdsc@177004";
		gcc_usb30_prim_gdsc = "/soc/qcom,gdsc@139004";
		gcc_usb3_phy_gdsc = "/soc/qcom,gdsc@150018";
		gpu_cc_cx_gdsc_hw_ctrl = "/soc/syscon@3d9953c";
		gpu_cc_cx_gdsc = "/soc/qcom,gdsc@3d99108";
		gpu_cc_gx_domain_addr = "/soc/syscon@3d99504";
		gpu_cc_gx_sw_reset = "/soc/syscon@3d99058";
		gpu_cc_gx_acd_reset = "/soc/syscon@3d99358";
		gpu_cc_gx_acd_iroot_reset = "/soc/syscon@3d9958c";
		gpu_cc_gx_gdsc = "/soc/qcom,gdsc@3d9905c";
		video_cc_mvs0_gdsc = "/soc/qcom,gdsc@abf80a4";
		video_cc_mvs0c_gdsc = "/soc/qcom,gdsc@abf804c";
		video_cc_mvs1_gdsc = "/soc/qcom,gdsc@abf80cc";
		video_cc_mvs1c_gdsc = "/soc/qcom,gdsc@abf8078";
		sdhc_2 = "/soc/sdhci@8804000";
		ufsphy_mem = "/soc/ufsphy_mem@1d80000";
		ufshc_mem = "/soc/ufshc@1d84000";
		tcsr_mutex_block = "/soc/syscon@1f40000";
		tcsr_mutex = "/soc/hwlock";
		smem = "/soc/qcom,smem";
		aoss_qmp = "/soc/power-controller@c300000";
		qmp_aop = "/soc/qcom,qmp-aop";
		qmp_tme = "/soc/qcom,qmp-tme";
		adsp_smp2p_out = "/soc/qcom,smp2p-adsp/master-kernel";
		adsp_smp2p_in = "/soc/qcom,smp2p-adsp/slave-kernel";
		sleepstate_smp2p_out = "/soc/qcom,smp2p-adsp/sleepstate-out";
		sleepstate_smp2p_in = "/soc/qcom,smp2p-adsp/qcom,sleepstate-in";
		smp2p_rdbg2_out = "/soc/qcom,smp2p-adsp/qcom,smp2p-rdbg2-out";
		smp2p_rdbg2_in = "/soc/qcom,smp2p-adsp/qcom,smp2p-rdbg2-in";
		cdsp_smp2p_out = "/soc/qcom,smp2p-cdsp/master-kernel";
		cdsp_smp2p_in = "/soc/qcom,smp2p-cdsp/slave-kernel";
		smp2p_rdbg5_out = "/soc/qcom,smp2p-cdsp/qcom,smp2p-rdbg5-out";
		smp2p_rdbg5_in = "/soc/qcom,smp2p-cdsp/qcom,smp2p-rdbg5-in";
		modem_smp2p_out = "/soc/qcom,smp2p-modem/master-kernel";
		modem_smp2p_in = "/soc/qcom,smp2p-modem/slave-kernel";
		smp2p_ipa_1_out = "/soc/qcom,smp2p-modem/qcom,smp2p-ipa-1-out";
		smp2p_ipa_1_in = "/soc/qcom,smp2p-modem/qcom,smp2p-ipa-1-in";
		tcsr = "/soc/syscon@1fc0000";
		eud = "/soc/qcom,msm-eud@88e0000";
		ipcc_mproc = "/soc/qcom,ipcc@408000";
		msm_fastrpc = "/soc/qcom,msm_fastrpc";
		adsp_pas = "/soc/remoteproc-adsp@03000000";
		glink_edge = "/soc/remoteproc-adsp@03000000/glink-edge";
		cdsp_pas = "/soc/remoteproc-cdsp@32300000";
		msm_cdsp_rm = "/soc/remoteproc-cdsp@32300000/glink-edge/qcom,msm_cdsprm_rpmsg/qcom,msm_cdsp_rm";
		modem_pas = "/soc/remoteproc-mss@04080000";
		spss_pas = "/soc/remoteproc-spss@1880000";
		trust_ui_vm = "/soc/qcom,trust_ui_vm@f80fc000";
		llcc_pmu = "/soc/llcc-pmu@24095000";
		qcom_pmu = "/soc/qcom,pmu";
		ddr_freq_table = "/soc/ddr-freq-table";
		llcc_freq_table = "/soc/llcc-freq-table";
		ddrqos_freq_table = "/soc/ddrqos-freq-table";
		qcom_dcvs = "/soc/qcom,dcvs";
		qcom_l3_dcvs_hw = "/soc/qcom,dcvs/l3";
		l3_dcvs_sp = "/soc/qcom,dcvs/l3/sp";
		qcom_ddr_dcvs_hw = "/soc/qcom,dcvs/ddr";
		ddr_dcvs_sp = "/soc/qcom,dcvs/ddr/sp";
		ddr_dcvs_fp = "/soc/qcom,dcvs/ddr/fp";
		qcom_llcc_dcvs_hw = "/soc/qcom,dcvs/llcc";
		llcc_dcvs_sp = "/soc/qcom,dcvs/llcc/sp";
		llcc_dcvs_fp = "/soc/qcom,dcvs/llcc/fp";
		qcom_ddrqos_dcvs_hw = "/soc/qcom,dcvs/ddrqos";
		ddrqos_dcvs_sp = "/soc/qcom,dcvs/ddrqos/sp";
		qcom_memlat = "/soc/qcom,memlat";
		ddrqos_gold_lat = "/soc/qcom,memlat/ddrqos/gold";
		ddrqos_prime_latfloor = "/soc/qcom,memlat/ddrqos/prime-latfloor";
		bwmon_llcc = "/soc/qcom,bwmon-llcc@240B6300";
		bwmon_ddr = "/soc/qcom,bwmon-ddr@24091000";
		thermal_zones = "/soc/thermal-zones";
		spmi_bus = "/soc/qcom,spmi@c42d000";
		spmi0_bus = "/soc/qcom,spmi@c42d000";
		spmi1_bus = "/soc/qcom,spmi@c432000";
		spmi0_debug_bus = "/soc/qcom,spmi-debug@10b14000";
		ipcc_self_ping_apss = "/soc/ipcc-self-ping-apss";
		ipcc_self_ping_cdsp = "/soc/ipcc-self-ping-cdsp";
		ipcc_self_ping_adsp = "/soc/ipcc-self-ping-adsp";
		ipcc_self_ping_slpi = "/soc/ipcc-self-ping-slpi";
		kgsl_smmu = "/soc/kgsl-smmu@3da0000";
		gpu_qtb = "/soc/kgsl-smmu@3da0000/gpu_qtb@3de8000";
		apps_smmu = "/soc/apps-smmu@15000000";
		anoc_1_qtb = "/soc/apps-smmu@15000000/anoc_1_qtb@16f0000";
		anoc_2_qtb = "/soc/apps-smmu@15000000/anoc_2_qtb@171a000";
		cam_hf_qtb = "/soc/apps-smmu@15000000/cam_hf_qtb@17d2000";
		nsp_qtb = "/soc/apps-smmu@15000000/nsp_qtb@523000";
		lpass_qtb = "/soc/apps-smmu@15000000/lpass_qtb@503000";
		pcie_qtb = "/soc/apps-smmu@15000000/pcie_qtb@16cd000";
		sf_qtb = "/soc/apps-smmu@15000000/sf_qtb@17d1000";
		mdp_hf_qtb = "/soc/apps-smmu@15000000/mdp_hf_qtb@17d0000";
		audio_etm0_out_funnel_lpass_lpi = "/soc/audio_etm0/out-ports/port/endpoint";
		tpdm_lpass_lpi = "/soc/tpdm_lpass_lpi";
		tpdm_lpass_lpi_out_funnel_lpass_lpi = "/soc/tpdm_lpass_lpi/out-ports/port/endpoint";
		tpdm_swao_prio_0 = "/soc/tpdm@10b09000";
		tpdm_swao_prio_0_out_tpda_aoss_0 = "/soc/tpdm@10b09000/out-ports/port/endpoint";
		tpdm_swao_prio_1 = "/soc/tpdm@10b0a000";
		tpdm_swao_prio_1_out_tpda_aoss_1 = "/soc/tpdm@10b0a000/out-ports/port/endpoint";
		tpdm_swao_prio_2 = "/soc/tpdm@10b0b000";
		tpdm_swao_prio_2_out_tpda_aoss_2 = "/soc/tpdm@10b0b000/out-ports/port/endpoint";
		tpdm_swao_prio_3 = "/soc/tpdm@10b0c000";
		tpdm_swao_prio_3_out_tpda_aoss_3 = "/soc/tpdm@10b0c000/out-ports/port/endpoint";
		tpdm_lpass = "/soc/tpdm@10844000";
		tpdm_lpass_out_funnel_lpass = "/soc/tpdm@10844000/out-ports/port/endpoint";
		tpdm_ddr_ch02 = "/soc/tpdm@10d20000";
		tpdm_ddr_ch02_out_funnel_ddr_ch02 = "/soc/tpdm@10d20000/out-ports/port/endpoint";
		tpdm_ddr_ch13 = "/soc/tpdm@10d30000";
		tpdm_ddr_ch13_out_funnel_ddr_ch13 = "/soc/tpdm@10d30000/out-ports/port/endpoint";
		tpdm_ddr = "/soc/tpdm@10d00000";
		tpdm_ddr_dl0_0_out_funnel_ddr_dl0 = "/soc/tpdm@10d00000/out-ports/port/endpoint";
		tpdm_shrm = "/soc/tpdm@10d01000";
		tpdm_ddr_dl0_1_out_funnel_ddr_dl0 = "/soc/tpdm@10d01000/out-ports/port/endpoint";
		tpdm_video = "/soc/tpdm@10830000";
		tpdm_video_out_funnel_video = "/soc/tpdm@10830000/out-ports/port/endpoint";
		tpdm_mdss = "/soc/tpdm@10c60000";
		tpdm_mdss_out_funnel_multimedia = "/soc/tpdm@10c60000/out-ports/port/endpoint";
		tpdm_mm = "/soc/tpdm@10c08000";
		tpdm_dlmm_out_funnel_multimedia = "/soc/tpdm@10c08000/out-ports/port/endpoint";
		tpdm_rdpm = "/soc/tpdm@10c38000";
		tpdm_dlwt0_out_funnel_dl_west = "/soc/tpdm@10c38000/out-ports/port/endpoint";
		tpdm_rdpm_mx = "/soc/tpdm@10c39000";
		tpdm_dlwt1_out_funnel_dl_west = "/soc/tpdm@10c39000/out-ports/port/endpoint";
		tpdm_turing = "/soc/tpdm@10980000";
		tpdm_turing_out_funnel_turing = "/soc/tpdm@10980000/out-ports/port/endpoint";
		tpdm_turing_llm = "/soc/tpdm_turing_llm";
		tpdm_turing_llm_out_funnel_turing = "/soc/tpdm_turing_llm/out-ports/port/endpoint";
		tpdm_gpu = "/soc/tpdm@10900000";
		tpdm_gpu_out_funnel_gfx_dl = "/soc/tpdm@10900000/out-ports/port/endpoint";
		tpdm_prng = "/soc/tpdm@10841000";
		tpdm_prng_out_tpda_dl_center_19 = "/soc/tpdm@10841000/out-ports/port/endpoint";
		tpdm_qm = "/soc/tpdm@109d0000";
		tpdm_qm_out_tpda_dl_center_20 = "/soc/tpdm@109d0000/out-ports/port/endpoint";
		tpdm_gcc = "/soc/tpdm@1082c000";
		tpdm_gcc_out_tpda_dl_center_21 = "/soc/tpdm@1082c000/out-ports/port/endpoint";
		tpdm_vsense = "/soc/tpdm@10840000";
		tpdm_vsense_out_tpda_dl_center_22 = "/soc/tpdm@10840000/out-ports/port/endpoint";
		tpdm_ipa = "/soc/tpdm@10c22000";
		tpdm_ipa_out_tpda_dl_center_23 = "/soc/tpdm@10c22000/out-ports/port/endpoint";
		tpdm_dlct = "/soc/tpdm@10c28000";
		tpdm_dlct_out_tpda_dl_center_26 = "/soc/tpdm@10c28000/out-ports/port/endpoint";
		tpdm_ipcc = "/soc/tpdm@10c29000";
		tpdm_ipcc_out_tpda_dl_center_27 = "/soc/tpdm@10c29000/out-ports/port/endpoint";
		tpdm_swao_1 = "/soc/tpdm@10b0d000";
		tpdm_swao_out_tpda_aoss_4 = "/soc/tpdm@10b0d000/out-ports/port/endpoint";
		snoc = "/soc/snoc";
		snoc_out_funnel_in0 = "/soc/snoc/out-ports/port/endpoint";
		tpdm_spdm = "/soc/tpdm@1000f000";
		tpdm_spdm_out_tpda_qdss_1 = "/soc/tpdm@1000f000/out-ports/port/endpoint";
		stm = "/soc/stm@10002000";
		stm_out_funnel_in0 = "/soc/stm@10002000/out-ports/port/endpoint";
		tpdm_dcc = "/soc/tpdm@10003000";
		tpdm_dcc_out_tpda_qdss_0 = "/soc/tpdm@10003000/out-ports/port/endpoint";
		tpdm_ufs = "/soc/tpdm@10c23000";
		tpdm_ufs_out_tpda_dl_south = "/soc/tpdm@10c23000/out-ports/port/endpoint";
		turing_etm0 = "/soc/turing_etm0";
		turing_etm0_out_funnel_turing_dup = "/soc/turing_etm0/out-ports/port/endpoint";
		tpdm_spss = "/soc/tpdm@10880000";
		tpdm_spss_out_tpda_spss = "/soc/tpdm@10880000/out-ports/port/endpoint";
		tpda_spss = "/soc/tpda@10882000";
		tpda_spss_out_funnel_spss = "/soc/tpda@10882000/out-ports/port/endpoint";
		tpda_spss_in_tpdm_spss = "/soc/tpda@10882000/in-ports/port@0/endpoint";
		tpdm_dl_south = "/soc/tpdm@109c0000";
		tpdm_dl_south_out_tpda_dl_south_2 = "/soc/tpdm@109c0000/out-ports/port/endpoint";
		tpdm_dl_north = "/soc/tpdm@10ac0000";
		tpdm_dl_north_out_tpda_dl_north_2 = "/soc/tpdm@10ac0000/out-ports/port/endpoint";
		tpdm_llm_silver = "/soc/tpdm@138a0000";
		tpdm_llm_silver_out_tpda_apss_0 = "/soc/tpdm@138a0000/out-ports/port/endpoint";
		tpdm_llm_gold = "/soc/tpdm@138b0000";
		tpdm_llm_gold_out_tpda_apss_1 = "/soc/tpdm@138b0000/out-ports/port/endpoint";
		tpdm_apss_llm = "/soc/tpdm@138c0000";
		tpdm_apss_llm_out_tpda_apss_2 = "/soc/tpdm@138c0000/out-ports/port/endpoint";
		tpdm_actpm = "/soc/tpdm@13860000";
		tpdm_apss0_out_tpda_apss_3 = "/soc/tpdm@13860000/out-ports/port/endpoint";
		tpdm_apss = "/soc/tpdm@13861000";
		tpdm_apps1_out_tpda_apss_4 = "/soc/tpdm@13861000/out-ports/port/endpoint";
		tpdm_modem_0 = "/soc/tpdm@10800000";
		tpdm_modem_0_out_tpda_modem_0 = "/soc/tpdm@10800000/out-ports/port/endpoint";
		tpdm_modem_1 = "/soc/tpdm@10801000";
		tpdm_modem_1_out_tpda_modem_1 = "/soc/tpdm@10801000/out-ports/port/endpoint";
		modem_etm0_out_funnel_modem_q6_dup = "/soc/modem_etm0/out-ports/port/endpoint";
		modem2_etm0_out_funnel_modem = "/soc/modem2_etm0/out-ports/port/endpoint";
		modem_diag = "/soc/modem_diag";
		modem_diag_out_funnel_modem_q6 = "/soc/modem_diag/out-ports/port/endpoint";
		tpdm_sdcc2 = "/soc/tpdm@10c20000";
		tpdm_sdcc2_out_tpda_dl_north_1 = "/soc/tpdm@10c20000/out-ports/port/endpoint";
		tpdm_sdcc4 = "/soc/tpdm@10c21000";
		tpdm_sdcc4_out_tpda_dl_south_1 = "/soc/tpdm@10c21000/out-ports/port/endpoint";
		tpdm_tmess_prng = "/soc/tpdm@10cc9000";
		tpdm_tmess_prng_out_tpda_tmess_0 = "/soc/tpdm@10cc9000/out-ports/port/endpoint";
		tpdm_tmess_0 = "/soc/tpdm@10cc0000";
		tpdm_tmess0_out_tpda_tmess = "/soc/tpdm@10cc0000/out-ports/port/endpoint";
		tpdm_tmess_1 = "/soc/tpdm@10cc1000";
		tpdm_tmess1_out_tpda_tmess = "/soc/tpdm@10cc1000/out-ports/port/endpoint";
		tpdm_lpicc = "/soc/tpdm_lpicc";
		tpdm_lpicc_out_tpda_ddr_lpi = "/soc/tpdm_lpicc/out-ports/port/endpoint";
		tpda_ddr_lpi = "/soc/tpda@10d09000";
		tpda_ddr_lpi_in_tpdm_lpicc = "/soc/tpda@10d09000/in-ports/port/endpoint";
		tpda_ddr_lpi_out_funnel_ddr_lpi = "/soc/tpda@10d09000/out-ports/port/endpoint";
		funnel_ddr_lpi = "/soc/funnel@10b23000";
		funnel_ddr_lpi_in_tpda_ddr_lpi = "/soc/funnel@10b23000/in-ports/port@0/endpoint";
		funnel_ddr_lpi_out_funnel_aoss = "/soc/funnel@10b23000/out-ports/port/endpoint";
		funnel_lpass_lpi = "/soc/funnel@10b44000";
		funnel_lpass_lpi_in_audio_etm0 = "/soc/funnel@10b44000/in-ports/port@0/endpoint";
		funnel_lpass_lpi_in_tpdm_lpass_lpi = "/soc/funnel@10b44000/in-ports/port@7/endpoint";
		funnel_lpass_lpi_out_funnel_aoss = "/soc/funnel@10b44000/out-ports/port/endpoint";
		funnel_gfx_dl = "/soc/funnel@10902000";
		funnel_gfx_dl_in_tpdm_gpu = "/soc/funnel@10902000/in-ports/port/endpoint";
		funnel_gfx_dl_out_tpda_dl_center_17 = "/soc/funnel@10902000/out-ports/port/endpoint";
		funnel_video = "/soc/funnel@10832000";
		funnel_video_in_tpdm_video = "/soc/funnel@10832000/in-ports/port/endpoint";
		funnel_video_out_funnel_multimedia = "/soc/funnel@10832000/out-ports/port/endpoint";
		funnel_multimedia = "/soc/funnel@10c0a000";
		funnel_multimedia_in_funnel_video = "/soc/funnel@10c0a000/in-ports/port@0/endpoint";
		funnel_multimedia_in_tpdm_mdss = "/soc/funnel@10c0a000/in-ports/port@1/endpoint";
		funnel_multimedia_in_tpdm_dlmm = "/soc/funnel@10c0a000/in-ports/port@3/endpoint";
		funnel_multimedia_out_funnel_dl_west = "/soc/funnel@10c0a000/out-ports/port/endpoint";
		funnel_lpass = "/soc/funnel@10846000";
		funnel_lpass_in_tpdm_lpass = "/soc/funnel@10846000/in-ports/port/endpoint";
		funnel_lpass_out_tpda_dl_center_4 = "/soc/funnel@10846000/out-ports/port/endpoint";
		funnel_ddr_ch02 = "/soc/funnel@10d22000";
		funnel_ddr_ch02_in_tpdm_ddr_ch02 = "/soc/funnel@10d22000/in-ports/port/endpoint";
		funnel_ddr_ch02_out_funnel_ddr_dl0 = "/soc/funnel@10d22000/out-ports/port/endpoint";
		funnel_ddr_ch13 = "/soc/funnel@10d32000";
		funnel_ddr_ch13_in_tpdm_ddr_ch13 = "/soc/funnel@10d32000/in-ports/port/endpoint";
		funnel_ddr_ch13_out_funnel_ddr_dl0 = "/soc/funnel@10d32000/out-ports/port/endpoint";
		funnel_ddr_dl0 = "/soc/funnel@10d03000";
		funnel_ddr_dl0_in_funnel_ddr_ch13 = "/soc/funnel@10d03000/in-ports/port@1/endpoint";
		funnel_ddr_dl0_in_funnel_ddr_ch02 = "/soc/funnel@10d03000/in-ports/port@0/endpoint";
		funnel_ddr_dl0_in_tpdm_ddr_dl0_1 = "/soc/funnel@10d03000/in-ports/port@3/endpoint";
		funnel_ddr_dl0_in_tpdm_ddr_dl0_0 = "/soc/funnel@10d03000/in-ports/port@2/endpoint";
		funnel_ddr_dl0_out_tpda_dl_center_5 = "/soc/funnel@10d03000/out-ports/port@0/endpoint";
		funnel_ddr_dl0_out_tpda_dl_center_6 = "/soc/funnel@10d03000/out-ports/port@1/endpoint";
		funnel_ddr_dl0_out_tpda_dl_center_7 = "/soc/funnel@10d03000/out-ports/port@2/endpoint";
		funnel_ddr_dl0_out_tpda_dl_center_8 = "/soc/funnel@10d03000/out-ports/port@3/endpoint";
		funnel_turing_dup = "/soc/funnel@10986000";
		funnel_turing_dup_in_turing_etm0 = "/soc/funnel@10986000/in-ports/port@3/endpoint";
		funnel_turing_dup_out_funnel_turing = "/soc/funnel@10986000/out-ports/port/endpoint";
		funnel_turing = "/soc/funnel@10983000";
		funnel_turing_in_tpdm_turing = "/soc/funnel@10983000/in-ports/port@0/endpoint";
		funnel_turing_in_tpdm_turing_llm = "/soc/funnel@10983000/in-ports/port@1/endpoint";
		funnel_turing_in_funnel_turing_dup = "/soc/funnel@10983000/in-ports/port@4/endpoint";
		funnel_turing_out_tpda_dl_center_15 = "/soc/funnel@10983000/out-ports/port@0/endpoint";
		funnel_turing_out_tpda_dl_center_16 = "/soc/funnel@10983000/out-ports/port@1/endpoint";
		funnel_turing_out_funnel_dl_center = "/soc/funnel@10983000/out-ports/port@2/endpoint";
		funnel_spss = "/soc/funnel@10883000";
		funnel_spss_in_tpda_spss = "/soc/funnel@10883000/in-ports/port/endpoint";
		funnel_spss_out_funnel_dl_north = "/soc/funnel@10883000/out-ports/port/endpoint";
		funnel_dl_west = "/soc/funnel@10c3a000";
		funnel_dl_west_in_funnel_multimedia = "/soc/funnel@10c3a000/in-ports/port@0/endpoint";
		funnel_dl_west_in_tpdm_dlwt0 = "/soc/funnel@10c3a000/in-ports/port@1/endpoint";
		funnel_dl_west_in_tpdm_dlwt1 = "/soc/funnel@10c3a000/in-ports/port@2/endpoint";
		funnel_dl_west_out_tpda_dl_center_9 = "/soc/funnel@10c3a000/out-ports/port@0/endpoint";
		funnel_dl_west_out_tpda_dl_center_10 = "/soc/funnel@10c3a000/out-ports/port@1/endpoint";
		funnel_dl_west_out_tpda_dl_center_12 = "/soc/funnel@10c3a000/out-ports/port@2/endpoint";
		funnel_dl_west_out_tpda_dl_center_13 = "/soc/funnel@10c3a000/out-ports/port@3/endpoint";
		funnel_dl_west_out_tpda_dl_center_14 = "/soc/funnel@10c3a000/out-ports/port@4/endpoint";
		tpda_dl_south = "/soc/tpda@109c1000";
		tpda_dl_south_1_in_tpdm_sdcc4 = "/soc/tpda@109c1000/in-ports/port@1/endpoint";
		tpda_dl_south_in_tpdm_ufs = "/soc/tpda@109c1000/in-ports/port@2/endpoint";
		tpda_dl_south_2_in_tpdm_dl_south = "/soc/tpda@109c1000/in-ports/port@4/endpoint";
		tpda_dl_south_out_funnel_dl_south = "/soc/tpda@109c1000/out-ports/port/endpoint";
		funnel_dl_south = "/soc/funnel@109c2000";
		funnel_dl_south_in_tpda_dl_south = "/soc/funnel@109c2000/in-ports/port/endpoint";
		funnel_dl_south_out_funnel_in1 = "/soc/funnel@109c2000/out-ports/port/endpoint";
		tpda_tmess = "/soc/tpda@10cc4000";
		tpda_tmess_in_tpdm_tmess1 = "/soc/tpda@10cc4000/in-ports/port@1/endpoint";
		tpda_tmess_0_in_tpdm_tmess_prng = "/soc/tpda@10cc4000/in-ports/port@0/endpoint";
		tpda_tmess_in_tpdm_tmess0 = "/soc/tpda@10cc4000/in-ports/port@2/endpoint";
		tpda_tmess_out_funnel_tmess = "/soc/tpda@10cc4000/out-ports/port/endpoint";
		funnel_tmess = "/soc/funnel@10cc5000";
		funnel_tmess_in_tpda_tmess = "/soc/funnel@10cc5000/in-ports/port/endpoint";
		funnel_tmess_out_funnel_dl_north = "/soc/funnel@10cc5000/out-ports/port/endpoint";
		tpda_dl_north = "/soc/tpda@10ac1000";
		tpda_dl_north_1_in_tpdm_sdcc2 = "/soc/tpda@10ac1000/in-ports/port@1/endpoint";
		tpda_dl_north_2_in_tpdm_dl_north = "/soc/tpda@10ac1000/in-ports/port@2/endpoint";
		tpda_dl_north_out_funnel_dl_north = "/soc/tpda@10ac1000/out-ports/port/endpoint";
		funnel_dl_north = "/soc/funnel@10ac2000";
		funnel_dl_north_in_tpda_dl_north = "/soc/funnel@10ac2000/in-ports/port@0/endpoint";
		funnel_dl_north_in_funnel_spss = "/soc/funnel@10ac2000/in-ports/port@3/endpoint";
		funnel_dl_north_in_funnel_tmess = "/soc/funnel@10ac2000/in-ports/port@5/endpoint";
		funnel_dl_north_out_funnel_in1 = "/soc/funnel@10ac2000/out-ports/port/endpoint";
		tpda_modem = "/soc/tpda@10803000";
		tpda_modem_0_in_tpdm_modem_0 = "/soc/tpda@10803000/in-ports/port@0/endpoint";
		tpda_modem_1_in_tpdm_modem_1 = "/soc/tpda@10803000/in-ports/port@1/endpoint";
		tpda_modem_out_funnel_modem = "/soc/tpda@10803000/out-ports/port/endpoint";
		funnel_modem_q6_dup = "/soc/funnel@1080d000";
		funnel_modem_q6_dup_in_modem_etm0 = "/soc/funnel@1080d000/in-ports/port@0/endpoint";
		funnel_modem_q6_dup_out_funnel_modem_q6 = "/soc/funnel@1080d000/out-ports/port/endpoint";
		funnel_modem_q6 = "/soc/funnel@1080c000";
		funnel_modem_q6_in_funnel_modem_q6_dup = "/soc/funnel@1080c000/in-ports/port@1/endpoint";
		funnel_modem_q6_in_modem_diag = "/soc/funnel@1080c000/in-ports/port@2/endpoint";
		funnel_modem_q6_out_funnel_modem = "/soc/funnel@1080c000/out-ports/port/endpoint";
		funnel_modem = "/soc/funnel@10804000";
		funnel_modem_in_modem2_etm0 = "/soc/funnel@10804000/in-ports/port@1/endpoint";
		funnel_modem_in_tpda_modem = "/soc/funnel@10804000/in-ports/port@0/endpoint";
		funnel_modem_in_funnel_modem_q6 = "/soc/funnel@10804000/in-ports/port@3/endpoint";
		funnel_modem_out_funnel_in1 = "/soc/funnel@10804000/out-ports/port/endpoint";
		tpda_apss = "/soc/tpda@13863000";
		tpda_apss_0_in_tpdm_llm_silver = "/soc/tpda@13863000/in-ports/port@0/endpoint";
		tpda_apss_1_in_tpdm_llm_gold = "/soc/tpda@13863000/in-ports/port@1/endpoint";
		tpda_apss_3_in_tpdm_apss0 = "/soc/tpda@13863000/in-ports/port@3/endpoint";
		tpda_apss_2_in_tpdm_apss_llm = "/soc/tpda@13863000/in-ports/port@2/endpoint";
		tpda_apss_4_in_tpdm_apps1 = "/soc/tpda@13863000/in-ports/port@4/endpoint";
		tpda_apss_out_funnel_apss = "/soc/tpda@13863000/out-ports/port/endpoint";
		funnel_apss = "/soc/funnel@13810000";
		funnel_apss_in_funnel_ete = "/soc/funnel@13810000/in-ports/port@0/endpoint";
		funnel_apss_in_tpda_apss = "/soc/funnel@13810000/in-ports/port@2/endpoint";
		funnel_apss_out_funnel_in1 = "/soc/funnel@13810000/out-ports/port/endpoint";
		tpda_dl_center = "/soc/tpda@10c2b000";
		tpda_dl_center_10_in_funnel_dl_west = "/soc/tpda@10c2b000/in-ports/port@a/endpoint";
		tpda_dl_center_13_in_funnel_dl_west = "/soc/tpda@10c2b000/in-ports/port@d/endpoint";
		tpda_dl_center_12_in_funnel_dl_west = "/soc/tpda@10c2b000/in-ports/port@c/endpoint";
		tpda_dl_center_15_in_funnel_turing = "/soc/tpda@10c2b000/in-ports/port@f/endpoint";
		tpda_dl_center_14_in_funnel_dl_west = "/soc/tpda@10c2b000/in-ports/port@e/endpoint";
		tpda_dl_center_17_in_funnel_gfx_dl = "/soc/tpda@10c2b000/in-ports/port@11/endpoint";
		tpda_dl_center_16_in_funnel_turing = "/soc/tpda@10c2b000/in-ports/port@10/endpoint";
		tpda_dl_center_19_in_tpdm_prng = "/soc/tpda@10c2b000/in-ports/port@13/endpoint";
		tpda_dl_center_23_in_tpdm_ipa = "/soc/tpda@10c2b000/in-ports/port@17/endpoint";
		tpda_dl_center_22_in_tpdm_vsense = "/soc/tpda@10c2b000/in-ports/port@16/endpoint";
		tpda_dl_center_26_in_tpdm_dlct = "/soc/tpda@10c2b000/in-ports/port@1a/endpoint";
		tpda_dl_center_20_in_tpdm_qm = "/soc/tpda@10c2b000/in-ports/port@14/endpoint";
		tpda_dl_center_27_in_tpdm_ipcc = "/soc/tpda@10c2b000/in-ports/port@1b/endpoint";
		tpda_dl_center_5_in_funnel_ddr_dl0 = "/soc/tpda@10c2b000/in-ports/port@5/endpoint";
		tpda_dl_center_4_in_funnel_lpass = "/soc/tpda@10c2b000/in-ports/port@4/endpoint";
		tpda_dl_center_7_in_funnel_ddr_dl0 = "/soc/tpda@10c2b000/in-ports/port@7/endpoint";
		tpda_dl_center_6_in_funnel_ddr_dl0 = "/soc/tpda@10c2b000/in-ports/port@6/endpoint";
		tpda_dl_center_9_in_funnel_dl_west = "/soc/tpda@10c2b000/in-ports/port@9/endpoint";
		tpda_dl_center_8_in_funnel_ddr_dl0 = "/soc/tpda@10c2b000/in-ports/port@8/endpoint";
		tpda_dl_center_21_in_tpdm_gcc = "/soc/tpda@10c2b000/in-ports/port@15/endpoint";
		tpda_dl_center_out_funnel_dl_center = "/soc/tpda@10c2b000/out-ports/port/endpoint";
		funnel_dl_center = "/soc/funnel@10c2c000";
		funnel_dl_center_in_tpda_dl_center = "/soc/funnel@10c2c000/in-ports/port@0/endpoint";
		funnel_dl_center_in_funnel_turing = "/soc/funnel@10c2c000/in-ports/port@6/endpoint";
		funnel_dl_center_out_funnel_in1 = "/soc/funnel@10c2c000/out-ports/port/endpoint";
		tpda_qdss = "/soc/tpda@10004000";
		tpda_qdss_1_in_tpdm_spdm = "/soc/tpda@10004000/in-ports/port@1/endpoint";
		tpda_qdss_0_in_tpdm_dcc = "/soc/tpda@10004000/in-ports/port@0/endpoint";
		tpda_qdss_out_funnel_in0 = "/soc/tpda@10004000/out-ports/port/endpoint";
		funnel_in0 = "/soc/funnel@10041000";
		funnel_in0_in_snoc = "/soc/funnel@10041000/in-ports/port@0/endpoint";
		funnel_in0_in_stm = "/soc/funnel@10041000/in-ports/port@7/endpoint";
		funnel_in0_in_tpda_qdss = "/soc/funnel@10041000/in-ports/port@6/endpoint";
		funnel_in0_out_funnel_qdss = "/soc/funnel@10041000/out-ports/port/endpoint";
		funnel_in1 = "/soc/funnel@10042000";
		funnel_in1_in_funnel_dl_south = "/soc/funnel@10042000/in-ports/port@0/endpoint";
		funnel_in1_in_funnel_dl_north = "/soc/funnel@10042000/in-ports/port@1/endpoint";
		funnel_in1_in_funnel_apss = "/soc/funnel@10042000/in-ports/port@4/endpoint";
		funnel_in1_in_funnel_modem = "/soc/funnel@10042000/in-ports/port@5/endpoint";
		funnel_in1_in_funnel_dl_center = "/soc/funnel@10042000/in-ports/port@6/endpoint";
		funnel_in1_out_funnel_qdss = "/soc/funnel@10042000/out-ports/port/endpoint";
		funnel_qdss = "/soc/funnel@10045000";
		funnel_qdss_in_funnel_in1 = "/soc/funnel@10045000/in-ports/port@1/endpoint";
		funnel_qdss_in_funnel_in0 = "/soc/funnel@10045000/in-ports/port@0/endpoint";
		funnel_qdss_out_funnel_aoss = "/soc/funnel@10045000/out-ports/port/endpoint";
		tpda_aoss = "/soc/tpda@10b08000";
		tpda_aoss_0_in_tpdm_swao_prio_0 = "/soc/tpda@10b08000/in-ports/port@0/endpoint";
		tpda_aoss_1_in_tpdm_swao_prio_1 = "/soc/tpda@10b08000/in-ports/port@1/endpoint";
		tpda_aoss_2_in_tpdm_swao_prio_2 = "/soc/tpda@10b08000/in-ports/port@2/endpoint";
		tpda_aoss_3_in_tpdm_swao_prio_3 = "/soc/tpda@10b08000/in-ports/port@3/endpoint";
		tpda_aoss_4_in_tpdm_swao = "/soc/tpda@10b08000/in-ports/port@4/endpoint";
		tpda_aoss_out_funnel_aoss = "/soc/tpda@10b08000/out-ports/port/endpoint";
		funnel_aoss = "/soc/funnel@10b04000";
		funnel_aoss_in_funnel_ddr_lpi = "/soc/funnel@10b04000/in-ports/port@3/endpoint";
		funnel_aoss_in_funnel_lpass_lpi = "/soc/funnel@10b04000/in-ports/port@5/endpoint";
		funnel_aoss_in_funnel_qdss = "/soc/funnel@10b04000/in-ports/port@7/endpoint";
		funnel_aoss_in_tpda_aoss = "/soc/funnel@10b04000/in-ports/port@6/endpoint";
		funnel_aoss_out_tmc_etf = "/soc/funnel@10b04000/out-ports/port/endpoint";
		dummy_eud = "/soc/dummy_sink";
		eud_in_replicator_swao = "/soc/dummy_sink/in-ports/port/endpoint";
		tmc_etf = "/soc/tmc@10b05000";
		tmc_etf_in_funnel_aoss = "/soc/tmc@10b05000/in-ports/port/endpoint";
		tmc_etf_out_replicator_swao = "/soc/tmc@10b05000/out-ports/port/endpoint";
		replicator_swao = "/soc/replicator@10b06000";
		replicator_swao_in_tmc_etf = "/soc/replicator@10b06000/in-ports/port/endpoint";
		replicator_swao_out_replicator_qdss = "/soc/replicator@10b06000/out-ports/port@0/endpoint";
		replicator_swao_out_eud = "/soc/replicator@10b06000/out-ports/port@1/endpoint";
		replicator_qdss = "/soc/replicator@10046000";
		replicator_qdss_in_replicator_swao = "/soc/replicator@10046000/in-ports/port/endpoint";
		replicator_qdss_out_replicator_etr = "/soc/replicator@10046000/out-ports/port@0/endpoint";
		replicator_etr = "/soc/replicator@1004e000";
		replicator_etr_in_replicator_qdss = "/soc/replicator@1004e000/in-ports/port/endpoint";
		replicator_etr_out_tmc_etr = "/soc/replicator@1004e000/out-ports/port@0/endpoint";
		replicator_etr_out_tmc_etr1 = "/soc/replicator@1004e000/out-ports/port@1/endpoint";
		tmc_etr = "/soc/tmc@10048000";
		tmc_etr_in_replicator_etr = "/soc/tmc@10048000/in-ports/port/endpoint";
		tmc_etr1 = "/soc/tmc@1004f000";
		tmc_etr1_in_replicator_etr = "/soc/tmc@1004f000/in-ports/port/endpoint";
		csr = "/soc/csr@10001000";
		swao_csr = "/soc/csr@10b11000";
		qc_cti = "/soc/cti@10010000";
		cti0 = "/soc/cti@10c2a000";
		ddr_dl_0_cti_0 = "/soc/cti@10d02000";
		ddr_ch02_dl_cti_0 = "/soc/cti@10d21000";
		ddr_ch13_dl_cti_0 = "/soc/cti@10d31000";
		lpass_dl_cti = "/soc/cti@10845000";
		gpu_isdb_cti = "/soc/cti@10961000";
		gpu_cortex_m3 = "/soc/cti@10962000";
		gpu_dl = "/soc/cti@10901000";
		iris_dl_cti = "/soc/cti@10831000";
		mdss_dl_cti = "/soc/cti@10c61000";
		turing_dl_cti_0 = "/soc/cti@10982000";
		turing_q6_cti = "/soc/cti@1098b000";
		swao_cti = "/soc/cti@10b00000";
		ddr_dl2_lpi = "/soc/cti@10b21000";
		ddr_dl_1 = "/soc/cti@10d08000";
		cortex_m3 = "/soc/cti@10b13000";
		lpass_lpi_cti1 = "/soc/cti@10b41000";
		lpass_lpi_cti3 = "/soc/cti@10b51000";
		lpass_q6_cti = "/soc/cti@10b4b000";
		lpass_ssc_sdc_cti = "/soc/cti@10b42000";
		apss_cti0 = "/soc/cti@138e0000";
		apss_cti1 = "/soc/cti@138f0000";
		apss_cti2 = "/soc/cti@13900000";
		camera_dl = "/soc/cti@10c15000";
		riscv_cti = "/soc/cti@1382b000";
		riscv_sifive_cti = "/soc/cti@1382e000";
		mss_q6_cti = "/soc/cti@1080b000";
		mss_vq6_cti = "/soc/cti@10813000";
		tmess_cti_0 = "/soc/cti@10cc2000";
		tmess_cti_1 = "/soc/cti@10cc3000";
		tmess_cti_2 = "/soc/cti@10cc4000";
		tmess_cti_3 = "/soc/cti@10cc5000";
		tmess_cti_4 = "/soc/cti@10cc6000";
		tmess_cpu = "/soc/cti@10cd1000";
		modem_tp_cti = "/soc/cti@10802000";
		apss_atb_cti = "/soc/cti@13862000";
		ddrss_shrm2 = "/soc/cti@10d11000";
		ipcb_tgu = "/soc/tgu@10b0e000";
		ete0_out_funnel_ete = "/soc/ete0/out-ports/port/endpoint";
		ete1_out_funnel_ete = "/soc/ete1/out-ports/port/endpoint";
		ete2_out_funnel_ete = "/soc/ete2/out-ports/port/endpoint";
		ete3_out_funnel_ete = "/soc/ete3/out-ports/port/endpoint";
		ete4_out_funnel_ete = "/soc/ete4/out-ports/port/endpoint";
		ete5_out_funnel_ete = "/soc/ete5/out-ports/port/endpoint";
		ete6_out_funnel_ete = "/soc/ete6/out-ports/port/endpoint";
		ete7_out_funnel_ete = "/soc/ete7/out-ports/port/endpoint";
		funnel_ete_out_funnel_apss = "/soc/funnel_ete/out-ports/port/endpoint";
		funnel_ete_in_ete0 = "/soc/funnel_ete/in-ports/port@0/endpoint";
		funnel_ete_in_ete1 = "/soc/funnel_ete/in-ports/port@1/endpoint";
		funnel_ete_in_ete2 = "/soc/funnel_ete/in-ports/port@2/endpoint";
		funnel_ete_in_ete3 = "/soc/funnel_ete/in-ports/port@3/endpoint";
		funnel_ete_in_ete4 = "/soc/funnel_ete/in-ports/port@4/endpoint";
		funnel_ete_in_ete5 = "/soc/funnel_ete/in-ports/port@5/endpoint";
		funnel_ete_in_ete6 = "/soc/funnel_ete/in-ports/port@6/endpoint";
		funnel_ete_in_ete7 = "/soc/funnel_ete/in-ports/port@7/endpoint";
		dcc = "/soc/dcc_v2@100ff000";
		qupv3_1 = "/soc/qcom,qupv3_1_geni_se@ac0000";
		qupv3_se7_2uart = "/soc/qcom,qupv3_1_geni_se@ac0000/qcom,qup_uart@a9c000";
		usb0 = "/soc/ssusb@a600000";
		usb_qmp_dp_phy = "/soc/ssphy@88e8000";
		msm_cvp = "/soc/qcom,cvp@ab00000";
		pcie0 = "/soc/qcom,pcie@1c00000";
		pcie0_rp = "/soc/qcom,pcie@1c00000/pcie0_rp";
		pcie0_msi = "/soc/qcom,pcie0_msi@0x17110040";
		L1B = "/regulator-pm-humu-l1";
		pm_humu_l1 = "/regulator-pm-humu-l1";
		L2B = "/regulator-pm-humu-l2";
		pm_humu_l2 = "/regulator-pm-humu-l2";
		L3B = "/regulator-pm-humu-l3";
		pm_humu_l3 = "/regulator-pm-humu-l3";
		L4B = "/regulator-pm-humu-l4";
		pm_humu_l4 = "/regulator-pm-humu-l4";
		L5B = "/regulator-pm-humu-l5";
		pm_humu_l5 = "/regulator-pm-humu-l5";
		L6B = "/regulator-pm-humu-l6";
		pm_humu_l6 = "/regulator-pm-humu-l6";
		L7B = "/regulator-pm-humu-l7";
		pm_humu_l7 = "/regulator-pm-humu-l7";
		L8B = "/regulator-pm-humu-l8";
		pm_humu_l8 = "/regulator-pm-humu-l8";
		L9B = "/regulator-pm-humu-l9";
		pm_humu_l9 = "/regulator-pm-humu-l9";
		L10B = "/regulator-pm-humu-l10";
		pm_humu_l10 = "/regulator-pm-humu-l10";
		L11B = "/regulator-pm-humu-l11";
		pm_humu_l11 = "/regulator-pm-humu-l11";
		L12B = "/regulator-pm-humu-l12";
		pm_humu_l12 = "/regulator-pm-humu-l12";
		L13B = "/regulator-pm-humu-l13";
		pm_humu_l13 = "/regulator-pm-humu-l13";
		L14B = "/regulator-pm-humu-l14";
		pm_humu_l14 = "/regulator-pm-humu-l14";
		L15B = "/regulator-pm-humu-l15";
		pm_humu_l15 = "/regulator-pm-humu-l15";
		L16B = "/regulator-pm-humu-l16";
		pm_humu_l16 = "/regulator-pm-humu-l16";
		L17B = "/regulator-pm-humu-l17";
		pm_humu_l17 = "/regulator-pm-humu-l17";
		BOB1 = "/regulator-pm-humu-bob1";
		pm_humu_bob1 = "/regulator-pm-humu-bob1";
		BOB2 = "/regulator-pm-humu-bob2";
		pm_humu_bob2 = "/regulator-pm-humu-bob2";
		L1C = "/regulator-pm-v6c-l1";
		pm_v6c_l1 = "/regulator-pm-v6c-l1";
		L2C = "/regulator-pm-v6c-l2";
		pm_v6c_l2 = "/regulator-pm-v6c-l2";
		L3C = "/regulator-pm-v6c-l3";
		pm_v6c_l3 = "/regulator-pm-v6c-l3";
		L1D = "/regulator-pm-v6d-l1";
		pm_v6d_l1 = "/regulator-pm-v6d-l1";
		L3D = "/regulator-pm-v6d-l3";
		pm_v6d_l3 = "/regulator-pm-v6d-l3";
		S4E = "/regulator-pm-v6e-s4";
		pm_v6e_s4 = "/regulator-pm-v6e-s4";
		S5E = "/regulator-pm-v6e-s5";
		pm_v6e_s5 = "/regulator-pm-v6e-s5";
		L1E = "/regulator-pm-v6e-l1";
		pm_v6e_l1 = "/regulator-pm-v6e-l1";
		L2E = "/regulator-pm-v6e-l2";
		pm_v6e_l2 = "/regulator-pm-v6e-l2";
		L3E = "/regulator-pm-v6e-l3";
		pm_v6e_l3 = "/regulator-pm-v6e-l3";
		S4F = "/regulator-pm-v8-s4";
		pm_v8_s4 = "/regulator-pm-v8-s4";
		L1F = "/regulator-pm-v8-l1";
		pm_v8_l1 = "/regulator-pm-v8-l1";
		L2F = "/regulator-pm-v8-l2";
		pm_v8_l2 = "/regulator-pm-v8-l2";
		L3F = "/regulator-pm-v8-l3";
		pm_v8_l3 = "/regulator-pm-v8-l3";
		S1G = "/regulator-pm-v6g-s1";
		pm_v6g_s1 = "/regulator-pm-v6g-s1";
		S2G = "/regulator-pm-v6g-s2";
		pm_v6g_s2 = "/regulator-pm-v6g-s2";
		S3G = "/regulator-pm-v6g-s3";
		pm_v6g_s3 = "/regulator-pm-v6g-s3";
		S4G = "/regulator-pm-v6g-s4";
		pm_v6g_s4 = "/regulator-pm-v6g-s4";
		S5G = "/regulator-pm-v6g-s5";
		pm_v6g_s5 = "/regulator-pm-v6g-s5";
		S6G = "/regulator-pm-v6g-s6";
		pm_v6g_s6 = "/regulator-pm-v6g-s6";
		L1G = "/regulator-pm-v6g-l1";
		pm_v6g_l1 = "/regulator-pm-v6g-l1";
		L2G = "/regulator-pm-v6g-l2";
		pm_v6g_l2 = "/regulator-pm-v6g-l2";
		L3G = "/regulator-pm-v6g-l3";
		pm_v6g_l3 = "/regulator-pm-v6g-l3";
		L1K = "/regulator-pmr-nalojrk-l1";
		pmr_nalojrk_l1 = "/regulator-pmr-nalojrk-l1";
		L2K = "/regulator-pmr-nalojrk-l2";
		pmr_nalojrk_l2 = "/regulator-pmr-nalojrk-l2";
		L3K = "/regulator-pmr-nalojrk-l3";
		pmr_nalojrk_l3 = "/regulator-pmr-nalojrk-l3";
		L4K = "/regulator-pmr-nalojrk-l4";
		pmr_nalojrk_l4 = "/regulator-pmr-nalojrk-l4";
		L5K = "/regulator-pmr-nalojrk-l5";
		pmr_nalojrk_l5 = "/regulator-pmr-nalojrk-l5";
		L6K = "/regulator-pmr-nalojrk-l6";
		pmr_nalojrk_l6 = "/regulator-pmr-nalojrk-l6";
		L7K = "/regulator-pmr-nalojrk-l7";
		pmr_nalojrk_l7 = "/regulator-pmr-nalojrk-l7";
		L1L = "/regulator-pmr-nalojrl-l1";
		pmr_nalojrl_l1 = "/regulator-pmr-nalojrl-l1";
		L2L = "/regulator-pmr-nalojrl-l2";
		pmr_nalojrl_l2 = "/regulator-pmr-nalojrl-l2";
		L3L = "/regulator-pmr-nalojrl-l3";
		pmr_nalojrl_l3 = "/regulator-pmr-nalojrl-l3";
		L4L = "/regulator-pmr-nalojrl-l4";
		pmr_nalojrl_l4 = "/regulator-pmr-nalojrl-l4";
		L5L = "/regulator-pmr-nalojrl-l5";
		pmr_nalojrl_l5 = "/regulator-pmr-nalojrl-l5";
		L6L = "/regulator-pmr-nalojrl-l6";
		pmr_nalojrl_l6 = "/regulator-pmr-nalojrl-l6";
		L7L = "/regulator-pmr-nalojrl-l7";
		pmr_nalojrl_l7 = "/regulator-pmr-nalojrl-l7";
		L1M = "/regulator-pm8010m-l1";
		pm8010m_l1 = "/regulator-pm8010m-l1";
		L2M = "/regulator-pm8010m-l2";
		pm8010m_l2 = "/regulator-pm8010m-l2";
		L3M = "/regulator-pm8010m-l3";
		pm8010m_l3 = "/regulator-pm8010m-l3";
		L4M = "/regulator-pm8010m-l4";
		pm8010m_l4 = "/regulator-pm8010m-l4";
		L5M = "/regulator-pm8010m-l5";
		pm8010m_l5 = "/regulator-pm8010m-l5";
		L6M = "/regulator-pm8010m-l6";
		pm8010m_l6 = "/regulator-pm8010m-l6";
		L7M = "/regulator-pm8010m-l7";
		pm8010m_l7 = "/regulator-pm8010m-l7";
		L1N = "/regulator-pm8010n-l1";
		pm8010n_l1 = "/regulator-pm8010n-l1";
		L2N = "/regulator-pm8010n-l2";
		pm8010n_l2 = "/regulator-pm8010n-l2";
		L3N = "/regulator-pm8010n-l3";
		pm8010n_l3 = "/regulator-pm8010n-l3";
		L4N = "/regulator-pm8010n-l4";
		pm8010n_l4 = "/regulator-pm8010n-l4";
		L5N = "/regulator-pm8010n-l5";
		pm8010n_l5 = "/regulator-pm8010n-l5";
		L6N = "/regulator-pm8010n-l6";
		pm8010n_l6 = "/regulator-pm8010n-l6";
		L7N = "/regulator-pm8010n-l7";
		pm8010n_l7 = "/regulator-pm8010n-l7";
	};
};
